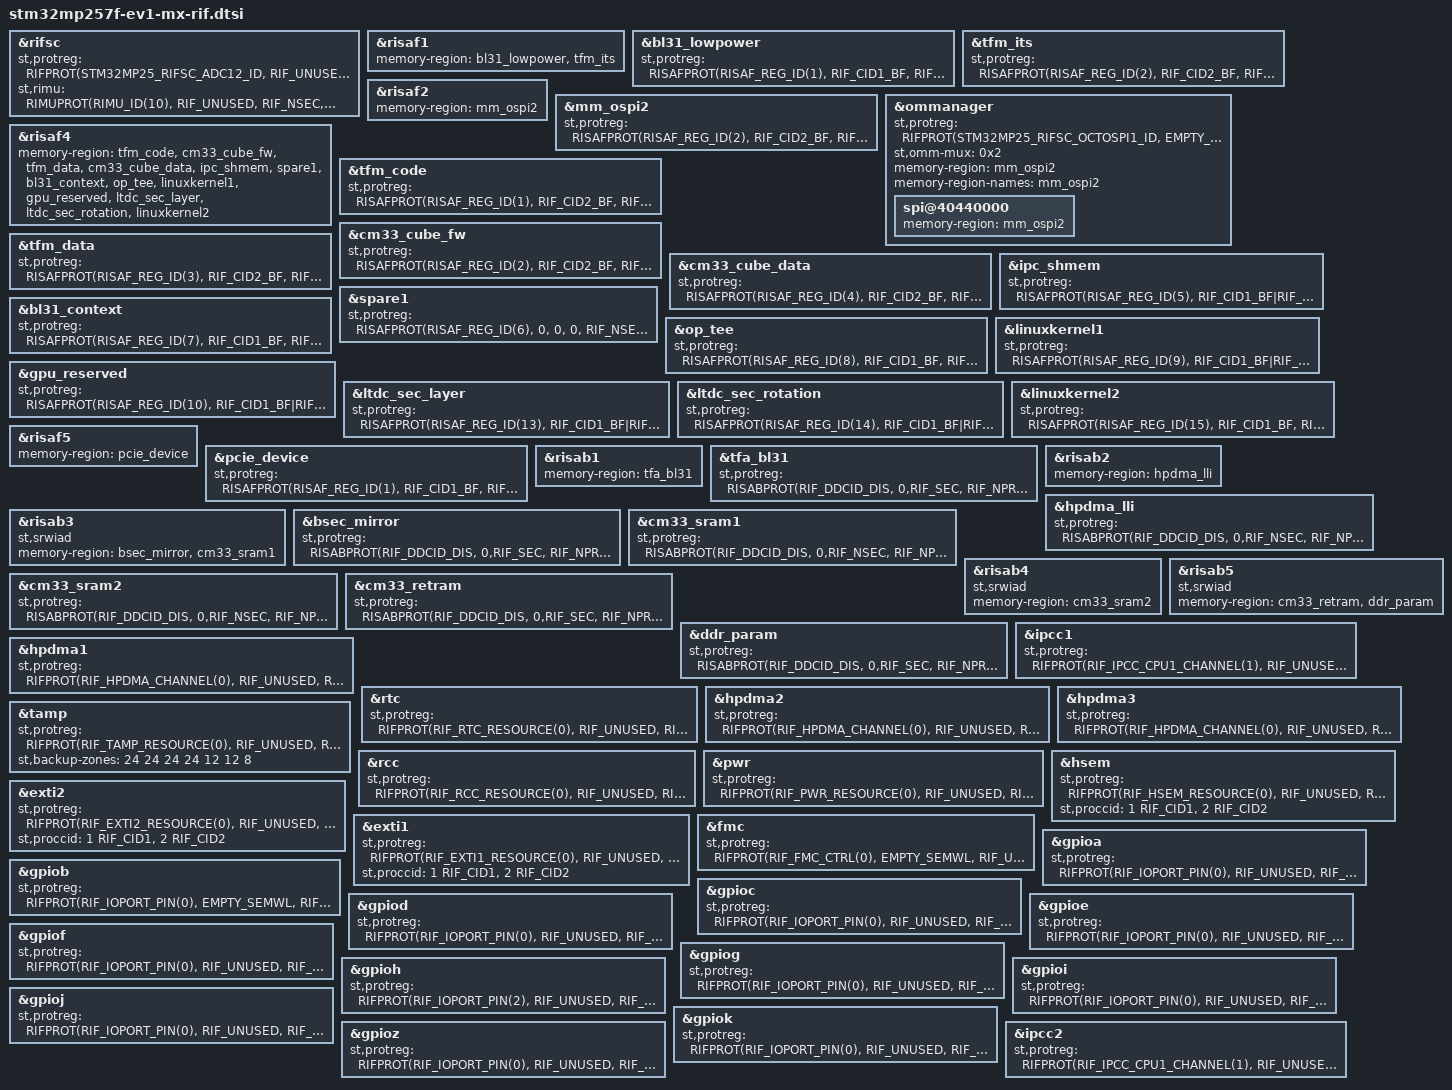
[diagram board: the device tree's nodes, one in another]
// SPDX-License-Identifier: (GPL-2.0-or-later OR BSD-3-Clause)
/*
 * Copyright (C) 2024, STMicroelectronics - All Rights Reserved
 * Author: STM32CubeMX code generation for STMicroelectronics.
 */

/* For more information on Device Tree configuration, please refer to
 * https://wiki.st.com/stm32mpu/wiki/Category:Device_tree_configuration
 */

&rifsc{
	status = "okay";
	st,protreg = <
		RIFPROT(STM32MP25_RIFSC_ADC12_ID, RIF_UNUSED, RIF_UNLOCK, RIF_NSEC, RIF_PRIV, RIF_CID1, RIF_SEM_DIS, RIF_CFEN)
		RIFPROT(STM32MP25_RIFSC_ADC3_ID, RIF_UNUSED, RIF_UNLOCK, RIF_NSEC, RIF_NPRIV, RIF_CID2, RIF_SEM_DIS, RIF_CFEN)
		RIFPROT(STM32MP25_RIFSC_ADF1_ID, EMPTY_SEMWL, RIF_UNLOCK, RIF_NSEC, RIF_NPRIV, RIF_UNUSED, RIF_SEM_EN, RIF_CFEN)
		RIFPROT(STM32MP25_RIFSC_COMBOPHY_ID, RIF_UNUSED, RIF_UNLOCK, RIF_NSEC, RIF_PRIV, RIF_CID1, RIF_SEM_DIS, RIF_CFEN)
		RIFPROT(STM32MP25_RIFSC_CRC_ID, RIF_UNUSED, RIF_UNLOCK, RIF_NSEC, RIF_NPRIV, RIF_CID2, RIF_SEM_DIS, RIF_CFEN)
		RIFPROT(STM32MP25_RIFSC_CRYP1_ID, RIF_UNUSED, RIF_UNLOCK, RIF_NSEC, RIF_PRIV, RIF_CID1, RIF_SEM_DIS, RIF_CFEN)
		RIFPROT(STM32MP25_RIFSC_CRYP2_ID, RIF_UNUSED, RIF_UNLOCK, RIF_SEC, RIF_PRIV, RIF_CID2, RIF_SEM_DIS, RIF_CFEN)
		RIFPROT(STM32MP25_RIFSC_CSI_ID, RIF_UNUSED, RIF_UNLOCK, RIF_NSEC, RIF_PRIV, RIF_CID1, RIF_SEM_DIS, RIF_CFEN)
		RIFPROT(STM32MP25_RIFSC_DCMIPP_ID, RIF_UNUSED, RIF_UNLOCK, RIF_NSEC, RIF_PRIV, RIF_CID1, RIF_SEM_DIS, RIF_CFEN)
		RIFPROT(STM32MP25_RIFSC_DCMI_PSSI_ID, EMPTY_SEMWL, RIF_UNLOCK, RIF_NSEC, RIF_NPRIV, RIF_UNUSED, RIF_SEM_EN, RIF_CFEN)
		RIFPROT(STM32MP25_RIFSC_DSI_RDFIFO_ID, RIF_UNUSED, RIF_UNLOCK, RIF_NSEC, RIF_PRIV, RIF_CID1, RIF_SEM_DIS, RIF_CFEN)
		RIFPROT(STM32MP25_RIFSC_DSI_TRIG_ID, RIF_UNUSED, RIF_UNLOCK, RIF_NSEC, RIF_PRIV, RIF_CID1, RIF_SEM_DIS, RIF_CFEN)
		RIFPROT(STM32MP25_RIFSC_DSI_CMN_ID, RIF_UNUSED, RIF_UNLOCK, RIF_NSEC, RIF_PRIV, RIF_CID1, RIF_SEM_DIS, RIF_CFEN)
		RIFPROT(STM32MP25_RIFSC_DTS_ID, RIF_UNUSED, RIF_UNLOCK, RIF_NSEC, RIF_PRIV, RIF_CID1, RIF_SEM_DIS, RIF_CFEN)
		RIFPROT(STM32MP25_RIFSC_ETH1_ID, RIF_UNUSED, RIF_UNLOCK, RIF_NSEC, RIF_PRIV, RIF_CID1, RIF_SEM_DIS, RIF_CFEN)
		RIFPROT(STM32MP25_RIFSC_ETH2_ID, RIF_UNUSED, RIF_UNLOCK, RIF_NSEC, RIF_PRIV, RIF_CID1, RIF_SEM_DIS, RIF_CFEN)
		RIFPROT(STM32MP25_RIFSC_ETHSW_ACM_CFG_ID, RIF_UNUSED, RIF_UNLOCK, RIF_NSEC, RIF_PRIV, RIF_CID1, RIF_SEM_DIS, RIF_CFEN)
		RIFPROT(STM32MP25_RIFSC_ETHSW_ACM_MSGBUF_ID, RIF_UNUSED, RIF_UNLOCK, RIF_NSEC, RIF_PRIV, RIF_CID1, RIF_SEM_DIS, RIF_CFEN)
		RIFPROT(STM32MP25_RIFSC_ETHSW_DEIP_ID, RIF_UNUSED, RIF_UNLOCK, RIF_NSEC, RIF_PRIV, RIF_CID1, RIF_SEM_DIS, RIF_CFEN)
		RIFPROT(STM32MP25_RIFSC_FDCAN_ID, EMPTY_SEMWL, RIF_UNLOCK, RIF_NSEC, RIF_PRIV, RIF_UNUSED, RIF_SEM_EN, RIF_CFEN)
		RIFPROT(STM32MP25_RIFSC_GICV2M_ID, RIF_UNUSED, RIF_UNLOCK, RIF_NSEC, RIF_PRIV, RIF_CID1, RIF_SEM_DIS, RIF_CFEN)
		RIFPROT(STM32MP25_RIFSC_GPU_ID, RIF_UNUSED, RIF_UNLOCK, RIF_NSEC, RIF_PRIV, RIF_CID1, RIF_SEM_DIS, RIF_CFEN)
		RIFPROT(STM32MP25_RIFSC_HASH_ID, RIF_UNUSED, RIF_LOCK, RIF_SEC, RIF_PRIV, RIF_CID1, RIF_SEM_DIS, RIF_CFEN)
		RIFPROT(STM32MP25_RIFSC_HDP_ID, EMPTY_SEMWL, RIF_UNLOCK, RIF_NSEC, RIF_NPRIV, RIF_UNUSED, RIF_SEM_EN, RIF_CFEN)
		RIFPROT(STM32MP25_RIFSC_I2C1_ID, RIF_UNUSED, RIF_UNLOCK, RIF_NSEC, RIF_NPRIV, RIF_CID2, RIF_SEM_DIS, RIF_CFEN)
		RIFPROT(STM32MP25_RIFSC_I2C2_ID, RIF_UNUSED, RIF_UNLOCK, RIF_NSEC, RIF_PRIV, RIF_CID1, RIF_SEM_DIS, RIF_CFEN)
		RIFPROT(STM32MP25_RIFSC_I2C3_ID, EMPTY_SEMWL, RIF_UNLOCK, RIF_NSEC, RIF_NPRIV, RIF_UNUSED, RIF_SEM_EN, RIF_CFEN)
		RIFPROT(STM32MP25_RIFSC_I2C4_ID, EMPTY_SEMWL, RIF_UNLOCK, RIF_NSEC, RIF_NPRIV, RIF_UNUSED, RIF_SEM_EN, RIF_CFEN)
		RIFPROT(STM32MP25_RIFSC_I2C5_ID, EMPTY_SEMWL, RIF_UNLOCK, RIF_NSEC, RIF_NPRIV, RIF_UNUSED, RIF_SEM_EN, RIF_CFEN)
		RIFPROT(STM32MP25_RIFSC_I2C6_ID, EMPTY_SEMWL, RIF_UNLOCK, RIF_NSEC, RIF_NPRIV, RIF_UNUSED, RIF_SEM_EN, RIF_CFEN)
		RIFPROT(STM32MP25_RIFSC_I2C7_ID, RIF_UNUSED, RIF_UNLOCK, RIF_SEC, RIF_PRIV, RIF_CID1, RIF_SEM_DIS, RIF_CFEN)
		RIFPROT(STM32MP25_RIFSC_I2C8_ID, EMPTY_SEMWL, RIF_UNLOCK, RIF_NSEC, RIF_PRIV, RIF_UNUSED, RIF_SEM_EN, RIF_CFEN)
		RIFPROT(STM32MP25_RIFSC_I3C1_ID, EMPTY_SEMWL, RIF_UNLOCK, RIF_NSEC, RIF_NPRIV, RIF_UNUSED, RIF_SEM_EN, RIF_CFEN)
		RIFPROT(STM32MP25_RIFSC_I3C2_ID, EMPTY_SEMWL, RIF_UNLOCK, RIF_NSEC, RIF_NPRIV, RIF_UNUSED, RIF_SEM_EN, RIF_CFEN)
		RIFPROT(STM32MP25_RIFSC_I3C3_ID, EMPTY_SEMWL, RIF_UNLOCK, RIF_NSEC, RIF_NPRIV, RIF_UNUSED, RIF_SEM_EN, RIF_CFEN)
		RIFPROT(STM32MP25_RIFSC_I3C4_ID, EMPTY_SEMWL, RIF_UNLOCK, RIF_NSEC, RIF_NPRIV, RIF_UNUSED, RIF_SEM_EN, RIF_CFEN)
		RIFPROT(STM32MP25_RIFSC_IAC_ID, RIF_UNUSED, RIF_UNLOCK, RIF_SEC, RIF_PRIV, RIF_CID1, RIF_SEM_DIS, RIF_CFEN)
		RIFPROT(STM32MP25_RIFSC_ICACHE_DCACHE_ID, RIF_UNUSED, RIF_UNLOCK, RIF_NSEC, RIF_NPRIV, RIF_CID2, RIF_SEM_DIS, RIF_CFEN)
		RIFPROT(STM32MP25_RIFSC_IWDG1_ID, RIF_UNUSED, RIF_LOCK, RIF_SEC, RIF_PRIV, RIF_CID1, RIF_SEM_DIS, RIF_CFEN)
		RIFPROT(STM32MP25_RIFSC_IWDG2_ID, RIF_UNUSED, RIF_UNLOCK, RIF_NSEC, RIF_PRIV, RIF_CID1, RIF_SEM_DIS, RIF_CFEN)
		RIFPROT(STM32MP25_RIFSC_IWDG3_ID, RIF_UNUSED, RIF_UNLOCK, RIF_SEC, RIF_PRIV, RIF_CID2, RIF_SEM_DIS, RIF_CFEN)
		RIFPROT(STM32MP25_RIFSC_IWDG4_ID, RIF_UNUSED, RIF_UNLOCK, RIF_NSEC, RIF_NPRIV, RIF_CID2, RIF_SEM_DIS, RIF_CFEN)
		RIFPROT(STM32MP25_RIFSC_IWDG5_ID, EMPTY_SEMWL, RIF_UNLOCK, RIF_NSEC, RIF_NPRIV, RIF_UNUSED, RIF_SEM_EN, RIF_CFEN)
		RIFPROT(STM32MP25_RIFSC_LPTIM1_ID, RIF_UNUSED, RIF_UNLOCK, RIF_SEC, RIF_PRIV, RIF_CID1, RIF_SEM_DIS, RIF_CFEN)
		RIFPROT(STM32MP25_RIFSC_LPTIM2_ID, RIF_UNUSED, RIF_UNLOCK, RIF_NSEC, RIF_PRIV, RIF_CID1, RIF_SEM_DIS, RIF_CFEN)
		RIFPROT(STM32MP25_RIFSC_LPTIM3_ID, RIF_UNUSED, RIF_UNLOCK, RIF_NSEC, RIF_PRIV, RIF_CID1, RIF_SEM_DIS, RIF_CFEN)
		RIFPROT(STM32MP25_RIFSC_LPTIM4_ID, RIF_UNUSED, RIF_UNLOCK, RIF_NSEC, RIF_PRIV, RIF_CID1, RIF_SEM_DIS, RIF_CFEN)
		RIFPROT(STM32MP25_RIFSC_LPTIM5_ID, RIF_UNUSED, RIF_UNLOCK, RIF_NSEC, RIF_PRIV, RIF_CID1, RIF_SEM_DIS, RIF_CFEN)
		RIFPROT(STM32MP25_RIFSC_LPUART1_ID, EMPTY_SEMWL, RIF_UNLOCK, RIF_NSEC, RIF_PRIV, RIF_UNUSED, RIF_SEM_EN, RIF_CFEN)
		RIFPROT(STM32MP25_RIFSC_LTDC_L2_ID, RIF_UNUSED, RIF_UNLOCK, RIF_NSEC, RIF_PRIV, RIF_CID1, RIF_SEM_DIS, RIF_CFEN)
		RIFPROT(STM32MP25_RIFSC_LTDC_L0L1_ID, RIF_UNUSED, RIF_UNLOCK, RIF_NSEC, RIF_PRIV, RIF_CID1, RIF_SEM_DIS, RIF_CFEN)
		RIFPROT(STM32MP25_RIFSC_LTDC_ROT_ID, RIF_UNUSED, RIF_UNLOCK, RIF_NSEC, RIF_PRIV, RIF_CID1, RIF_SEM_DIS, RIF_CFEN)
		RIFPROT(STM32MP25_RIFSC_LTDC_CMN_ID, RIF_UNUSED, RIF_UNLOCK, RIF_NSEC, RIF_PRIV, RIF_CID1, RIF_SEM_DIS, RIF_CFEN)
		RIFPROT(STM32MP25_RIFSC_LVDS_ID, RIF_UNUSED, RIF_UNLOCK, RIF_NSEC, RIF_PRIV, RIF_CID1, RIF_SEM_DIS, RIF_CFEN)
		RIFPROT(STM32MP25_RIFSC_MDF1_ID, EMPTY_SEMWL, RIF_UNLOCK, RIF_NSEC, RIF_PRIV, RIF_UNUSED, RIF_SEM_EN, RIF_CFEN)
		RIFPROT(STM32MP25_RIFSC_PCIE_ID, RIF_UNUSED, RIF_UNLOCK, RIF_NSEC, RIF_PRIV, RIF_CID1, RIF_SEM_DIS, RIF_CFEN)
		RIFPROT(STM32MP25_RIFSC_PKA_ID, RIF_UNUSED, RIF_LOCK, RIF_SEC, RIF_PRIV, RIF_CID1, RIF_SEM_DIS, RIF_CFEN)
		RIFPROT(STM32MP25_RIFSC_RAMCFG_ID, RIF_UNUSED, RIF_UNLOCK, RIF_SEC, RIF_PRIV, RIF_CID1, RIF_SEM_DIS, RIF_CFEN)
		RIFPROT(STM32MP25_RIFSC_RNG_ID, RIF_UNUSED, RIF_LOCK, RIF_SEC, RIF_PRIV, RIF_CID1, RIF_SEM_DIS, RIF_CFEN)
		RIFPROT(STM32MP25_RIFSC_SAES_ID, RIF_CID1_BF|RIF_CID2_BF, RIF_LOCK, RIF_SEC, RIF_PRIV, RIF_UNUSED, RIF_SEM_EN, RIF_CFEN)
		RIFPROT(STM32MP25_RIFSC_SAI1_ID, EMPTY_SEMWL, RIF_UNLOCK, RIF_NSEC, RIF_NPRIV, RIF_UNUSED, RIF_SEM_EN, RIF_CFEN)
		RIFPROT(STM32MP25_RIFSC_SAI2_ID, EMPTY_SEMWL, RIF_UNLOCK, RIF_NSEC, RIF_PRIV, RIF_UNUSED, RIF_SEM_EN, RIF_CFEN)
		RIFPROT(STM32MP25_RIFSC_SAI3_ID, EMPTY_SEMWL, RIF_UNLOCK, RIF_NSEC, RIF_NPRIV, RIF_UNUSED, RIF_SEM_EN, RIF_CFEN)
		RIFPROT(STM32MP25_RIFSC_SAI4_ID, EMPTY_SEMWL, RIF_UNLOCK, RIF_NSEC, RIF_NPRIV, RIF_UNUSED, RIF_SEM_EN, RIF_CFEN)
		RIFPROT(STM32MP25_RIFSC_SDMMC1_ID, RIF_UNUSED, RIF_UNLOCK, RIF_NSEC, RIF_PRIV, RIF_CID1, RIF_SEM_DIS, RIF_CFEN)
		RIFPROT(STM32MP25_RIFSC_SDMMC2_ID, EMPTY_SEMWL, RIF_UNLOCK, RIF_NSEC, RIF_PRIV, RIF_UNUSED, RIF_SEM_EN, RIF_CFEN)
		RIFPROT(STM32MP25_RIFSC_SDMMC3_ID, EMPTY_SEMWL, RIF_UNLOCK, RIF_NSEC, RIF_PRIV, RIF_UNUSED, RIF_SEM_EN, RIF_CFEN)
		RIFPROT(STM32MP25_RIFSC_SERC_ID, RIF_UNUSED, RIF_UNLOCK, RIF_SEC, RIF_PRIV, RIF_CID1, RIF_SEM_DIS, RIF_CFEN)
		RIFPROT(STM32MP25_RIFSC_SPDIFRX_ID, EMPTY_SEMWL, RIF_UNLOCK, RIF_NSEC, RIF_NPRIV, RIF_UNUSED, RIF_SEM_EN, RIF_CFEN)
		RIFPROT(STM32MP25_RIFSC_SPI1_ID, EMPTY_SEMWL, RIF_UNLOCK, RIF_NSEC, RIF_NPRIV, RIF_UNUSED, RIF_SEM_EN, RIF_CFEN)
		RIFPROT(STM32MP25_RIFSC_SPI2_ID, EMPTY_SEMWL, RIF_UNLOCK, RIF_NSEC, RIF_PRIV, RIF_UNUSED, RIF_SEM_EN, RIF_CFEN)
		RIFPROT(STM32MP25_RIFSC_SPI3_ID, EMPTY_SEMWL, RIF_UNLOCK, RIF_NSEC, RIF_PRIV, RIF_UNUSED, RIF_SEM_EN, RIF_CFEN)
		RIFPROT(STM32MP25_RIFSC_SPI4_ID, EMPTY_SEMWL, RIF_UNLOCK, RIF_NSEC, RIF_NPRIV, RIF_UNUSED, RIF_SEM_EN, RIF_CFEN)
		RIFPROT(STM32MP25_RIFSC_SPI5_ID, EMPTY_SEMWL, RIF_UNLOCK, RIF_NSEC, RIF_NPRIV, RIF_UNUSED, RIF_SEM_EN, RIF_CFEN)
		RIFPROT(STM32MP25_RIFSC_SPI6_ID, EMPTY_SEMWL, RIF_UNLOCK, RIF_NSEC, RIF_NPRIV, RIF_UNUSED, RIF_SEM_EN, RIF_CFEN)
		RIFPROT(STM32MP25_RIFSC_SPI7_ID, EMPTY_SEMWL, RIF_UNLOCK, RIF_NSEC, RIF_NPRIV, RIF_UNUSED, RIF_SEM_EN, RIF_CFEN)
		RIFPROT(STM32MP25_RIFSC_SPI8_ID, EMPTY_SEMWL, RIF_UNLOCK, RIF_NSEC, RIF_PRIV, RIF_UNUSED, RIF_SEM_EN, RIF_CFEN)
		RIFPROT(STM32MP25_RIFSC_STGEN_ID, RIF_UNUSED, RIF_LOCK, RIF_SEC, RIF_PRIV, RIF_CID1, RIF_SEM_DIS, RIF_CFEN)
		RIFPROT(STM32MP25_RIFSC_TIM1_ID, RIF_UNUSED, RIF_UNLOCK, RIF_NSEC, RIF_PRIV, RIF_CID1, RIF_SEM_DIS, RIF_CFEN)
		RIFPROT(STM32MP25_RIFSC_TIM2_ID, RIF_UNUSED, RIF_UNLOCK, RIF_NSEC, RIF_NPRIV, RIF_CID2, RIF_SEM_DIS, RIF_CFEN)
		RIFPROT(STM32MP25_RIFSC_TIM3_ID, RIF_UNUSED, RIF_UNLOCK, RIF_NSEC, RIF_PRIV, RIF_CID1, RIF_SEM_DIS, RIF_CFEN)
		RIFPROT(STM32MP25_RIFSC_TIM4_ID, RIF_UNUSED, RIF_UNLOCK, RIF_NSEC, RIF_PRIV, RIF_CID1, RIF_SEM_DIS, RIF_CFEN)
		RIFPROT(STM32MP25_RIFSC_TIM5_ID, RIF_UNUSED, RIF_UNLOCK, RIF_NSEC, RIF_PRIV, RIF_CID1, RIF_SEM_DIS, RIF_CFEN)
		RIFPROT(STM32MP25_RIFSC_TIM6_ID, RIF_UNUSED, RIF_UNLOCK, RIF_NSEC, RIF_PRIV, RIF_CID2, RIF_SEM_DIS, RIF_CFEN)
		RIFPROT(STM32MP25_RIFSC_TIM7_ID, RIF_UNUSED, RIF_UNLOCK, RIF_NSEC, RIF_PRIV, RIF_CID1, RIF_SEM_DIS, RIF_CFEN)
		RIFPROT(STM32MP25_RIFSC_TIM8_ID, RIF_UNUSED, RIF_UNLOCK, RIF_NSEC, RIF_PRIV, RIF_CID1, RIF_SEM_DIS, RIF_CFEN)
		RIFPROT(STM32MP25_RIFSC_TIM10_ID, RIF_UNUSED, RIF_UNLOCK, RIF_NSEC, RIF_PRIV, RIF_CID1, RIF_SEM_DIS, RIF_CFEN)
		RIFPROT(STM32MP25_RIFSC_TIM11_ID, RIF_UNUSED, RIF_UNLOCK, RIF_NSEC, RIF_PRIV, RIF_CID1, RIF_SEM_DIS, RIF_CFEN)
		RIFPROT(STM32MP25_RIFSC_TIM12_ID, RIF_UNUSED, RIF_UNLOCK, RIF_NSEC, RIF_PRIV, RIF_CID1, RIF_SEM_DIS, RIF_CFEN)
		RIFPROT(STM32MP25_RIFSC_TIM13_ID, RIF_UNUSED, RIF_UNLOCK, RIF_NSEC, RIF_PRIV, RIF_CID1, RIF_SEM_DIS, RIF_CFEN)
		RIFPROT(STM32MP25_RIFSC_TIM14_ID, RIF_UNUSED, RIF_UNLOCK, RIF_NSEC, RIF_PRIV, RIF_CID1, RIF_SEM_DIS, RIF_CFEN)
		RIFPROT(STM32MP25_RIFSC_TIM15_ID, RIF_UNUSED, RIF_UNLOCK, RIF_NSEC, RIF_PRIV, RIF_CID1, RIF_SEM_DIS, RIF_CFEN)
		RIFPROT(STM32MP25_RIFSC_TIM16_ID, RIF_UNUSED, RIF_UNLOCK, RIF_NSEC, RIF_PRIV, RIF_CID1, RIF_SEM_DIS, RIF_CFEN)
		RIFPROT(STM32MP25_RIFSC_TIM17_ID, RIF_UNUSED, RIF_UNLOCK, RIF_NSEC, RIF_PRIV, RIF_CID1, RIF_SEM_DIS, RIF_CFEN)
		RIFPROT(STM32MP25_RIFSC_TIM20_ID, RIF_UNUSED, RIF_UNLOCK, RIF_NSEC, RIF_PRIV, RIF_CID1, RIF_SEM_DIS, RIF_CFEN)
		RIFPROT(STM32MP25_RIFSC_UART4_ID, EMPTY_SEMWL, RIF_UNLOCK, RIF_NSEC, RIF_NPRIV, RIF_UNUSED, RIF_SEM_EN, RIF_CFEN)
		RIFPROT(STM32MP25_RIFSC_UART5_ID, RIF_UNUSED, RIF_UNLOCK, RIF_SEC, RIF_NPRIV, RIF_CID2, RIF_SEM_DIS, RIF_CFEN)
		RIFPROT(STM32MP25_RIFSC_USART6_ID, RIF_UNUSED, RIF_UNLOCK, RIF_SEC, RIF_NPRIV, RIF_CID2, RIF_SEM_DIS, RIF_CFEN)
		RIFPROT(STM32MP25_RIFSC_UART7_ID, EMPTY_SEMWL, RIF_UNLOCK, RIF_NSEC, RIF_NPRIV, RIF_UNUSED, RIF_SEM_EN, RIF_CFEN)
		RIFPROT(STM32MP25_RIFSC_UART8_ID, EMPTY_SEMWL, RIF_UNLOCK, RIF_NSEC, RIF_NPRIV, RIF_UNUSED, RIF_SEM_EN, RIF_CFEN)
		RIFPROT(STM32MP25_RIFSC_UART9_ID, EMPTY_SEMWL, RIF_UNLOCK, RIF_NSEC, RIF_NPRIV, RIF_UNUSED, RIF_SEM_EN, RIF_CFEN)
		RIFPROT(STM32MP25_RIFSC_UCPD1_ID, RIF_UNUSED, RIF_UNLOCK, RIF_NSEC, RIF_NPRIV, RIF_CID2, RIF_SEM_DIS, RIF_CFEN)
		RIFPROT(STM32MP25_RIFSC_USART1_ID, RIF_UNUSED, RIF_UNLOCK, RIF_NSEC, RIF_NPRIV, RIF_CID1, RIF_SEM_DIS, RIF_CFEN)
		RIFPROT(STM32MP25_RIFSC_USART2_ID, RIF_UNUSED, RIF_UNLOCK, RIF_NSEC, RIF_PRIV, RIF_CID1, RIF_SEM_DIS, RIF_CFEN)
		RIFPROT(STM32MP25_RIFSC_USART3_ID, EMPTY_SEMWL, RIF_UNLOCK, RIF_NSEC, RIF_NPRIV, RIF_UNUSED, RIF_SEM_EN, RIF_CFEN)
		RIFPROT(STM32MP25_RIFSC_USB3DR_ID, RIF_UNUSED, RIF_UNLOCK, RIF_NSEC, RIF_PRIV, RIF_CID1, RIF_SEM_DIS, RIF_CFEN)
		RIFPROT(STM32MP25_RIFSC_USBH_ID, RIF_UNUSED, RIF_UNLOCK, RIF_NSEC, RIF_PRIV, RIF_CID1, RIF_SEM_DIS, RIF_CFEN)
		RIFPROT(STM32MP25_RIFSC_VDEC_ID, RIF_UNUSED, RIF_UNLOCK, RIF_NSEC, RIF_PRIV, RIF_CID1, RIF_SEM_DIS, RIF_CFEN)
		RIFPROT(STM32MP25_RIFSC_VENC_ID, RIF_UNUSED, RIF_UNLOCK, RIF_NSEC, RIF_PRIV, RIF_CID1, RIF_SEM_DIS, RIF_CFEN)
		RIFPROT(STM32MP25_RIFSC_VREFBUF_ID, RIF_UNUSED, RIF_UNLOCK, RIF_SEC, RIF_PRIV, RIF_CID1, RIF_SEM_DIS, RIF_CFEN)
		RIFPROT(STM32MP25_RIFSC_WWDG1_ID, RIF_UNUSED, RIF_UNLOCK, RIF_NSEC, RIF_NPRIV, RIF_CID2, RIF_SEM_DIS, RIF_CFEN)
		RIFPROT(STM32MP25_RIFSC_WWDG2_ID, EMPTY_SEMWL, RIF_UNLOCK, RIF_NSEC, RIF_NPRIV, RIF_UNUSED, RIF_SEM_EN, RIF_CFEN)
	>;
	st,rimu = <
		RIMUPROT(RIMU_ID(10), RIF_UNUSED, RIF_NSEC, RIF_PRIV,RIF_CIDSEL_P) /* RIMU IP = DCMIPP */
		RIMUPROT(RIMU_ID(6), RIF_UNUSED, RIF_NSEC, RIF_PRIV,RIF_CIDSEL_P) /* RIMU IP = ETH1 */
		RIMUPROT(RIMU_ID(7), RIF_UNUSED, RIF_NSEC, RIF_PRIV,RIF_CIDSEL_P) /* RIMU IP = ETH2 */
		RIMUPROT(RIMU_ID(0), RIF_CID1, RIF_NSEC, RIF_NPRIV,RIF_CIDSEL_M) /* RIMU IP = ETR */
		RIMUPROT(RIMU_ID(9), RIF_UNUSED, RIF_NSEC, RIF_PRIV,RIF_CIDSEL_P) /* RIMU IP = GPU */
		RIMUPROT(RIMU_ID(11), RIF_CID4, RIF_NSEC, RIF_PRIV,RIF_CIDSEL_M) /* RIMU IP = LTDC_L1L2 */
		RIMUPROT(RIMU_ID(12), RIF_CID4, RIF_NSEC, RIF_PRIV,RIF_CIDSEL_M) /* RIMU IP = LTDC_L3 */
		RIMUPROT(RIMU_ID(13), RIF_CID4, RIF_NSEC, RIF_PRIV,RIF_CIDSEL_M) /* RIMU IP = LTDC_ROT */
		RIMUPROT(RIMU_ID(8), RIF_UNUSED, RIF_NSEC, RIF_PRIV,RIF_CIDSEL_P) /* RIMU IP = PCIE */
		RIMUPROT(RIMU_ID(1), RIF_UNUSED, RIF_NSEC, RIF_PRIV,RIF_CIDSEL_P) /* RIMU IP = SDMMC1 */
		RIMUPROT(RIMU_ID(2), RIF_UNUSED, RIF_NSEC, RIF_PRIV,RIF_CIDSEL_P) /* RIMU IP = SDMMC2 */
		RIMUPROT(RIMU_ID(3), RIF_UNUSED, RIF_NSEC, RIF_PRIV,RIF_CIDSEL_P) /* RIMU IP = SDMMC3 */
		RIMUPROT(RIMU_ID(4), RIF_UNUSED, RIF_NSEC, RIF_PRIV,RIF_CIDSEL_P) /* RIMU IP = USB3DR */
		RIMUPROT(RIMU_ID(5), RIF_UNUSED, RIF_NSEC, RIF_PRIV,RIF_CIDSEL_P) /* RIMU IP = USBH */
		RIMUPROT(RIMU_ID(14), RIF_UNUSED, RIF_NSEC, RIF_PRIV,RIF_CIDSEL_P) /* RIMU IP = VDEC */
		RIMUPROT(RIMU_ID(15), RIF_UNUSED, RIF_NSEC, RIF_PRIV,RIF_CIDSEL_P) /* RIMU IP = VENC */

	>;

	/* USER CODE BEGIN rifsc */
	/* USER CODE END rifsc */
};

&risaf1{

	memory-region = <&bl31_lowpower>, <&tfm_its>;
};

&bl31_lowpower{

	st,protreg = <RISAFPROT(RISAF_REG_ID(1), RIF_CID1_BF, RIF_CID1_BF, RIF_CID1_BF, RIF_SEC, RIF_ENC_DIS, RIF_BREN_EN)>;
};

&tfm_its{

	st,protreg = <RISAFPROT(RISAF_REG_ID(2), RIF_CID2_BF, RIF_CID2_BF, RIF_CID2_BF, RIF_SEC, RIF_ENC_DIS, RIF_BREN_EN)>;
};

&risaf2{

	memory-region = <&mm_ospi2>;
};

&mm_ospi2{

	st,protreg = <RISAFPROT(RISAF_REG_ID(2), RIF_CID2_BF, RIF_CID2_BF, RIF_CID1_BF, RIF_SEC, RIF_ENC_DIS, RIF_BREN_EN)>;
};

&ommanager{

	st,protreg = <
		RIFPROT(STM32MP25_RIFSC_OCTOSPI1_ID, EMPTY_SEMWL, RIF_UNLOCK, RIF_NSEC, RIF_NPRIV, RIF_UNUSED, RIF_SEM_EN, RIF_CFEN)
		RIFPROT(STM32MP25_RIFSC_OCTOSPI2_ID, RIF_UNUSED, RIF_UNLOCK, RIF_SEC, RIF_PRIV, RIF_CID1, RIF_SEM_DIS, RIF_CFEN)
		RIFPROT(STM32MP25_RIFSC_OCTOSPIM_ID, RIF_UNUSED, RIF_UNLOCK, RIF_SEC, RIF_PRIV, RIF_CID1, RIF_SEM_DIS, RIF_CFEN)
		RIFPROT(STM32MP25_RIFSC_OTFDEC1_ID, EMPTY_SEMWL, RIF_UNLOCK, RIF_NSEC, RIF_PRIV, RIF_UNUSED, RIF_SEM_EN, RIF_CFEN)
		RIFPROT(STM32MP25_RIFSC_OTFDEC2_ID, RIF_UNUSED, RIF_UNLOCK, RIF_SEC, RIF_PRIV, RIF_CID2, RIF_SEM_DIS, RIF_CFEN)
	>;

	/* USER CODE BEGIN ommanager */
	st,omm-mux = <0x2>;
	memory-region = <&mm_ospi2>;
	memory-region-names = "mm_ospi2";

	spi@40440000 {
		memory-region = <&mm_ospi2>;
		/* insert flash definition here */
	};
	/* USER CODE END ommanager */
};

&risaf4{

	memory-region = <&tfm_code>, <&cm33_cube_fw>, <&tfm_data>, <&cm33_cube_data>, <&ipc_shmem>, <&spare1>, <&bl31_context>, <&op_tee>, <&linuxkernel1>, <&gpu_reserved>, <&ltdc_sec_layer>, <&ltdc_sec_rotation>, <&linuxkernel2>;
};

&tfm_code{

	st,protreg = <RISAFPROT(RISAF_REG_ID(1), RIF_CID2_BF, RIF_CID2_BF, 0, RIF_SEC, RIF_ENC_EN, RIF_BREN_EN)>;
};

&cm33_cube_fw{

	st,protreg = <RISAFPROT(RISAF_REG_ID(2), RIF_CID2_BF, RIF_CID2_BF, 0, RIF_NSEC, RIF_ENC_DIS, RIF_BREN_EN)>;
};

&tfm_data{

	st,protreg = <RISAFPROT(RISAF_REG_ID(3), RIF_CID2_BF, RIF_CID2_BF, 0, RIF_SEC, RIF_ENC_EN, RIF_BREN_EN)>;
};

&cm33_cube_data{

	st,protreg = <RISAFPROT(RISAF_REG_ID(4), RIF_CID2_BF, RIF_CID2_BF, 0, RIF_NSEC, RIF_ENC_DIS, RIF_BREN_EN)>;
};

&ipc_shmem{

	st,protreg = <RISAFPROT(RISAF_REG_ID(5), RIF_CID1_BF|RIF_CID2_BF, RIF_CID1_BF|RIF_CID2_BF, 0, RIF_NSEC, RIF_ENC_DIS, RIF_BREN_EN)>;
};

&spare1{

	st,protreg = <RISAFPROT(RISAF_REG_ID(6), 0, 0, 0, RIF_NSEC, RIF_ENC_DIS, RIF_BREN_EN)>;
};

&bl31_context{

	st,protreg = <RISAFPROT(RISAF_REG_ID(7), RIF_CID1_BF, RIF_CID1_BF, RIF_CID1_BF, RIF_SEC, RIF_ENC_EN, RIF_BREN_EN)>;
};

&op_tee{

	st,protreg = <RISAFPROT(RISAF_REG_ID(8), RIF_CID1_BF, RIF_CID1_BF, 0, RIF_SEC, RIF_ENC_EN, RIF_BREN_EN)>;
};

&linuxkernel1{

	st,protreg = <RISAFPROT(RISAF_REG_ID(9), RIF_CID1_BF|RIF_CID4_BF, RIF_CID1_BF|RIF_CID4_BF, 0, RIF_NSEC, RIF_ENC_DIS, RIF_BREN_EN)>;
};

&gpu_reserved{

	st,protreg = <RISAFPROT(RISAF_REG_ID(10), RIF_CID1_BF|RIF_CID4_BF, RIF_CID1_BF|RIF_CID4_BF, 0, RIF_NSEC, RIF_ENC_DIS, RIF_BREN_EN)>;
};

&ltdc_sec_layer{

	st,protreg = <RISAFPROT(RISAF_REG_ID(13), RIF_CID1_BF|RIF_CID4_BF, RIF_CID1_BF|RIF_CID4_BF, 0, RIF_NSEC, RIF_ENC_DIS, RIF_BREN_EN)>;
};

&ltdc_sec_rotation{

	st,protreg = <RISAFPROT(RISAF_REG_ID(14), RIF_CID1_BF|RIF_CID4_BF, RIF_CID1_BF|RIF_CID4_BF, 0, RIF_NSEC, RIF_ENC_DIS, RIF_BREN_EN)>;
};

&linuxkernel2{

	st,protreg = <RISAFPROT(RISAF_REG_ID(15), RIF_CID1_BF, RIF_CID1_BF, 0, RIF_NSEC, RIF_ENC_DIS, RIF_BREN_EN)>;
};

&risaf5{

	memory-region = <&pcie_device>;
};

&pcie_device{

	st,protreg = <RISAFPROT(RISAF_REG_ID(1), RIF_CID1_BF, RIF_CID1_BF, 0, RIF_NSEC, RIF_ENC_DIS, RIF_BREN_EN)>;
};

&risab1{

	memory-region = <&tfa_bl31>;
};

&tfa_bl31{

	st,protreg = <RISABPROT(RIF_DDCID_DIS, 0,RIF_SEC, RIF_NPRIV, RIF_CFEN, RIF_CID1_BF, RIF_CID1_BF, RIF_CID1_BF)>;
};

&risab2{

	memory-region = <&hpdma_lli>;
};

&hpdma_lli{

	st,protreg = <RISABPROT(RIF_DDCID_DIS, 0,RIF_NSEC, RIF_NPRIV, RIF_CFEN, RIF_CID1_BF, RIF_CID1_BF, RIF_CID1_BF)>;
};

&risab3{

	st,srwiad;
	memory-region = <&bsec_mirror>, <&cm33_sram1>;
};

&bsec_mirror{

	st,protreg = <RISABPROT(RIF_DDCID_DIS, 0,RIF_SEC, RIF_NPRIV, RIF_CFEN, RIF_CID1_BF|RIF_CID2_BF, RIF_CID1_BF, RIF_CID1_BF|RIF_CID2_BF)>;
};

&cm33_sram1{

	st,protreg = <RISABPROT(RIF_DDCID_DIS, 0,RIF_NSEC, RIF_NPRIV, RIF_CFEN, RIF_CID2_BF, RIF_CID2_BF, 0)>;
};

&risab4{

	st,srwiad;
	memory-region = <&cm33_sram2>;
};

&cm33_sram2{

	st,protreg = <RISABPROT(RIF_DDCID_DIS, 0,RIF_NSEC, RIF_NPRIV, RIF_CFEN, RIF_CID2_BF, RIF_CID2_BF, 0)>;
};

&risab5{

	st,srwiad;
	memory-region = <&cm33_retram>, <&ddr_param>;
};

&cm33_retram{

	st,protreg = <RISABPROT(RIF_DDCID_DIS, 0,RIF_SEC, RIF_NPRIV, RIF_CFEN, RIF_CID2_BF, RIF_CID2_BF, 0)>;
};

&ddr_param{

	st,protreg = <RISABPROT(RIF_DDCID_DIS, 0,RIF_SEC, RIF_NPRIV, RIF_CFEN, RIF_CID1_BF, RIF_CID1_BF, RIF_CID1_BF)>;
};

&ipcc1{

	st,protreg = <
		RIFPROT(RIF_IPCC_CPU1_CHANNEL(1), RIF_UNUSED, RIF_UNLOCK, RIF_NSEC, RIF_NPRIV, RIF_CID1, RIF_SEM_DIS, RIF_CFEN) /* Feature = CPU1 channel 1 */
		RIFPROT(RIF_IPCC_CPU1_CHANNEL(2), RIF_UNUSED, RIF_UNLOCK, RIF_NSEC, RIF_NPRIV, RIF_CID1, RIF_SEM_DIS, RIF_CFEN) /* Feature = CPU1 channel 2 */
		RIFPROT(RIF_IPCC_CPU1_CHANNEL(3), RIF_UNUSED, RIF_UNLOCK, RIF_NSEC, RIF_NPRIV, RIF_CID1, RIF_SEM_DIS, RIF_CFEN) /* Feature = CPU1 channel 3 */
		RIFPROT(RIF_IPCC_CPU1_CHANNEL(4), RIF_UNUSED, RIF_UNLOCK, RIF_NSEC, RIF_NPRIV, RIF_CID1, RIF_SEM_DIS, RIF_CFEN) /* Feature = CPU1 channel 4 */
		RIFPROT(RIF_IPCC_CPU1_CHANNEL(5), RIF_UNUSED, RIF_UNLOCK, RIF_NSEC, RIF_NPRIV, RIF_CID1, RIF_SEM_DIS, RIF_CFEN) /* Feature = CPU1 channel 5 */
		RIFPROT(RIF_IPCC_CPU1_CHANNEL(6), RIF_UNUSED, RIF_UNLOCK, RIF_NSEC, RIF_NPRIV, RIF_CID1, RIF_SEM_DIS, RIF_CFEN) /* Feature = CPU1 channel 6 */
		RIFPROT(RIF_IPCC_CPU1_CHANNEL(7), RIF_UNUSED, RIF_UNLOCK, RIF_NSEC, RIF_NPRIV, RIF_CID1, RIF_SEM_DIS, RIF_CFEN) /* Feature = CPU1 channel 7 */
		RIFPROT(RIF_IPCC_CPU1_CHANNEL(8), RIF_UNUSED, RIF_UNLOCK, RIF_NSEC, RIF_NPRIV, RIF_CID1, RIF_SEM_DIS, RIF_CFEN) /* Feature = CPU1 channel 8 */
		RIFPROT(RIF_IPCC_CPU1_CHANNEL(9), RIF_UNUSED, RIF_UNLOCK, RIF_NSEC, RIF_NPRIV, RIF_CID1, RIF_SEM_DIS, RIF_CFEN) /* Feature = CPU1 channel 9 */
		RIFPROT(RIF_IPCC_CPU1_CHANNEL(10), RIF_UNUSED, RIF_UNLOCK, RIF_NSEC, RIF_NPRIV, RIF_CID1, RIF_SEM_DIS, RIF_CFEN) /* Feature = CPU1 channel 10 */
		RIFPROT(RIF_IPCC_CPU1_CHANNEL(11), RIF_UNUSED, RIF_UNLOCK, RIF_NSEC, RIF_NPRIV, RIF_CID1, RIF_SEM_DIS, RIF_CFEN) /* Feature = CPU1 channel 11 */
		RIFPROT(RIF_IPCC_CPU1_CHANNEL(12), RIF_UNUSED, RIF_UNLOCK, RIF_NSEC, RIF_NPRIV, RIF_CID1, RIF_SEM_DIS, RIF_CFEN) /* Feature = CPU1 channel 12 */
		RIFPROT(RIF_IPCC_CPU1_CHANNEL(13), RIF_UNUSED, RIF_UNLOCK, RIF_NSEC, RIF_NPRIV, RIF_CID1, RIF_SEM_DIS, RIF_CFEN) /* Feature = CPU1 channel 13 */
		RIFPROT(RIF_IPCC_CPU1_CHANNEL(14), RIF_UNUSED, RIF_UNLOCK, RIF_NSEC, RIF_NPRIV, RIF_CID1, RIF_SEM_DIS, RIF_CFEN) /* Feature = CPU1 channel 14 */
		RIFPROT(RIF_IPCC_CPU1_CHANNEL(15), RIF_UNUSED, RIF_UNLOCK, RIF_NSEC, RIF_NPRIV, RIF_CID1, RIF_SEM_DIS, RIF_CFEN) /* Feature = CPU1 channel 15 */
		RIFPROT(RIF_IPCC_CPU1_CHANNEL(16), RIF_UNUSED, RIF_UNLOCK, RIF_NSEC, RIF_NPRIV, RIF_CID1, RIF_SEM_DIS, RIF_CFEN) /* Feature = CPU1 channel 16 */
		RIFPROT(RIF_IPCC_CPU2_CHANNEL(1), RIF_UNUSED, RIF_UNLOCK, RIF_NSEC, RIF_NPRIV, RIF_CID2, RIF_SEM_DIS, RIF_CFEN) /* Feature = CPU2 channel 1 */
		RIFPROT(RIF_IPCC_CPU2_CHANNEL(2), RIF_UNUSED, RIF_UNLOCK, RIF_NSEC, RIF_NPRIV, RIF_CID2, RIF_SEM_DIS, RIF_CFEN) /* Feature = CPU2 channel 2 */
		RIFPROT(RIF_IPCC_CPU2_CHANNEL(3), RIF_UNUSED, RIF_UNLOCK, RIF_NSEC, RIF_NPRIV, RIF_CID2, RIF_SEM_DIS, RIF_CFEN) /* Feature = CPU2 channel 3 */
		RIFPROT(RIF_IPCC_CPU2_CHANNEL(4), RIF_UNUSED, RIF_UNLOCK, RIF_NSEC, RIF_NPRIV, RIF_CID2, RIF_SEM_DIS, RIF_CFEN) /* Feature = CPU2 channel 4 */
		RIFPROT(RIF_IPCC_CPU2_CHANNEL(5), RIF_UNUSED, RIF_UNLOCK, RIF_NSEC, RIF_NPRIV, RIF_CID2, RIF_SEM_DIS, RIF_CFEN) /* Feature = CPU2 channel 5 */
		RIFPROT(RIF_IPCC_CPU2_CHANNEL(6), RIF_UNUSED, RIF_UNLOCK, RIF_NSEC, RIF_NPRIV, RIF_CID2, RIF_SEM_DIS, RIF_CFEN) /* Feature = CPU2 channel 6 */
		RIFPROT(RIF_IPCC_CPU2_CHANNEL(7), RIF_UNUSED, RIF_UNLOCK, RIF_NSEC, RIF_NPRIV, RIF_CID2, RIF_SEM_DIS, RIF_CFEN) /* Feature = CPU2 channel 7 */
		RIFPROT(RIF_IPCC_CPU2_CHANNEL(8), RIF_UNUSED, RIF_UNLOCK, RIF_NSEC, RIF_NPRIV, RIF_CID2, RIF_SEM_DIS, RIF_CFEN) /* Feature = CPU2 channel 8 */
		RIFPROT(RIF_IPCC_CPU2_CHANNEL(9), RIF_UNUSED, RIF_UNLOCK, RIF_NSEC, RIF_NPRIV, RIF_CID2, RIF_SEM_DIS, RIF_CFEN) /* Feature = CPU2 channel 9 */
		RIFPROT(RIF_IPCC_CPU2_CHANNEL(10), RIF_UNUSED, RIF_UNLOCK, RIF_NSEC, RIF_NPRIV, RIF_CID2, RIF_SEM_DIS, RIF_CFEN) /* Feature = CPU2 channel 10 */
		RIFPROT(RIF_IPCC_CPU2_CHANNEL(11), RIF_UNUSED, RIF_UNLOCK, RIF_NSEC, RIF_NPRIV, RIF_CID2, RIF_SEM_DIS, RIF_CFEN) /* Feature = CPU2 channel 11 */
		RIFPROT(RIF_IPCC_CPU2_CHANNEL(12), RIF_UNUSED, RIF_UNLOCK, RIF_NSEC, RIF_NPRIV, RIF_CID2, RIF_SEM_DIS, RIF_CFEN) /* Feature = CPU2 channel 12 */
		RIFPROT(RIF_IPCC_CPU2_CHANNEL(13), RIF_UNUSED, RIF_UNLOCK, RIF_NSEC, RIF_NPRIV, RIF_CID2, RIF_SEM_DIS, RIF_CFEN) /* Feature = CPU2 channel 13 */
		RIFPROT(RIF_IPCC_CPU2_CHANNEL(14), RIF_UNUSED, RIF_UNLOCK, RIF_NSEC, RIF_NPRIV, RIF_CID2, RIF_SEM_DIS, RIF_CFEN) /* Feature = CPU2 channel 14 */
		RIFPROT(RIF_IPCC_CPU2_CHANNEL(15), RIF_UNUSED, RIF_UNLOCK, RIF_NSEC, RIF_NPRIV, RIF_CID2, RIF_SEM_DIS, RIF_CFEN) /* Feature = CPU2 channel 15 */
		RIFPROT(RIF_IPCC_CPU2_CHANNEL(16), RIF_UNUSED, RIF_UNLOCK, RIF_NSEC, RIF_NPRIV, RIF_CID2, RIF_SEM_DIS, RIF_CFEN) /* Feature = CPU2 channel 16 */
	>;
};

&hpdma1{

	st,protreg = <
		RIFPROT(RIF_HPDMA_CHANNEL(0), RIF_UNUSED, RIF_UNLOCK, RIF_NSEC, RIF_PRIV, RIF_CID1, RIF_SEM_DIS, RIF_CFEN) /* Feature = HPDMA1 channel 0 */
		RIFPROT(RIF_HPDMA_CHANNEL(1), RIF_UNUSED, RIF_UNLOCK, RIF_NSEC, RIF_PRIV, RIF_CID1, RIF_SEM_DIS, RIF_CFEN) /* Feature = HPDMA1 channel 1 */
		RIFPROT(RIF_HPDMA_CHANNEL(2), RIF_UNUSED, RIF_UNLOCK, RIF_NSEC, RIF_PRIV, RIF_CID1, RIF_SEM_DIS, RIF_CFEN) /* Feature = HPDMA1 channel 2 */
		RIFPROT(RIF_HPDMA_CHANNEL(3), RIF_UNUSED, RIF_UNLOCK, RIF_NSEC, RIF_PRIV, RIF_CID1, RIF_SEM_DIS, RIF_CFEN) /* Feature = HPDMA1 channel 3 */
		RIFPROT(RIF_HPDMA_CHANNEL(4), RIF_UNUSED, RIF_UNLOCK, RIF_NSEC, RIF_PRIV, RIF_CID1, RIF_SEM_DIS, RIF_CFEN) /* Feature = HPDMA1 channel 4 */
		RIFPROT(RIF_HPDMA_CHANNEL(5), RIF_UNUSED, RIF_UNLOCK, RIF_NSEC, RIF_PRIV, RIF_CID1, RIF_SEM_DIS, RIF_CFEN) /* Feature = HPDMA1 channel 5 */
		RIFPROT(RIF_HPDMA_CHANNEL(6), RIF_UNUSED, RIF_UNLOCK, RIF_NSEC, RIF_PRIV, RIF_CID1, RIF_SEM_DIS, RIF_CFEN) /* Feature = HPDMA1 channel 6 */
		RIFPROT(RIF_HPDMA_CHANNEL(7), RIF_UNUSED, RIF_UNLOCK, RIF_NSEC, RIF_PRIV, RIF_CID1, RIF_SEM_DIS, RIF_CFEN) /* Feature = HPDMA1 channel 7 */
		RIFPROT(RIF_HPDMA_CHANNEL(8), RIF_UNUSED, RIF_UNLOCK, RIF_NSEC, RIF_PRIV, RIF_CID1, RIF_SEM_DIS, RIF_CFEN) /* Feature = HPDMA1 channel 8 */
		RIFPROT(RIF_HPDMA_CHANNEL(9), RIF_UNUSED, RIF_UNLOCK, RIF_NSEC, RIF_PRIV, RIF_CID1, RIF_SEM_DIS, RIF_CFEN) /* Feature = HPDMA1 channel 9 */
		RIFPROT(RIF_HPDMA_CHANNEL(10), RIF_UNUSED, RIF_UNLOCK, RIF_NSEC, RIF_PRIV, RIF_CID1, RIF_SEM_DIS, RIF_CFEN) /* Feature = HPDMA1 channel 10 */
		RIFPROT(RIF_HPDMA_CHANNEL(11), RIF_UNUSED, RIF_UNLOCK, RIF_NSEC, RIF_PRIV, RIF_CID1, RIF_SEM_DIS, RIF_CFEN) /* Feature = HPDMA1 channel 11 */
		RIFPROT(RIF_HPDMA_CHANNEL(12), RIF_UNUSED, RIF_UNLOCK, RIF_NSEC, RIF_PRIV, RIF_CID1, RIF_SEM_DIS, RIF_CFEN) /* Feature = HPDMA1 channel 12 */
		RIFPROT(RIF_HPDMA_CHANNEL(13), RIF_UNUSED, RIF_UNLOCK, RIF_NSEC, RIF_PRIV, RIF_CID1, RIF_SEM_DIS, RIF_CFEN) /* Feature = HPDMA1 channel 13 */
		RIFPROT(RIF_HPDMA_CHANNEL(14), RIF_UNUSED, RIF_UNLOCK, RIF_NSEC, RIF_PRIV, RIF_CID1, RIF_SEM_DIS, RIF_CFEN) /* Feature = HPDMA1 channel 14 */
		RIFPROT(RIF_HPDMA_CHANNEL(15), RIF_UNUSED, RIF_UNLOCK, RIF_NSEC, RIF_PRIV, RIF_CID1, RIF_SEM_DIS, RIF_CFEN) /* Feature = HPDMA1 channel 15 */
	>;
};

&rtc{

	st,protreg = <
		RIFPROT(RIF_RTC_RESOURCE(0), RIF_UNUSED, RIF_UNLOCK, RIF_NSEC, RIF_PRIV, RIF_CID1, RIF_SEM_DIS, RIF_CFEN) /* Feature = Alarm A */
		RIFPROT(RIF_RTC_RESOURCE(1), RIF_UNUSED, RIF_UNLOCK, RIF_NSEC, RIF_NPRIV, RIF_CID2, RIF_SEM_DIS, RIF_CFEN) /* Feature = Alarm B */
		RIFPROT(RIF_RTC_RESOURCE(2), RIF_UNUSED, RIF_UNLOCK, RIF_NSEC, RIF_PRIV, RIF_CID1, RIF_SEM_DIS, RIF_CFEN) /* Feature = Wakeup timer */
		RIFPROT(RIF_RTC_RESOURCE(3), RIF_UNUSED, RIF_UNLOCK, RIF_NSEC, RIF_PRIV, RIF_CID1, RIF_SEM_DIS, RIF_CFEN) /* Feature = Timestamp */
		RIFPROT(RIF_RTC_RESOURCE(4), RIF_UNUSED, RIF_UNLOCK, RIF_NSEC, RIF_PRIV, RIF_CID1, RIF_SEM_DIS, RIF_CFEN) /* Feature = Calibration */
		RIFPROT(RIF_RTC_RESOURCE(5), RIF_UNUSED, RIF_UNLOCK, RIF_NSEC, RIF_PRIV, RIF_CID1, RIF_SEM_DIS, RIF_CFEN) /* Feature = Initialization */
	>;
};

&hpdma2{

	st,protreg = <
		RIFPROT(RIF_HPDMA_CHANNEL(0), RIF_UNUSED, RIF_UNLOCK, RIF_NSEC, RIF_PRIV, RIF_CID1, RIF_SEM_DIS, RIF_CFEN) /* Feature = HPDMA2 channel 0 */
		RIFPROT(RIF_HPDMA_CHANNEL(1), RIF_UNUSED, RIF_UNLOCK, RIF_NSEC, RIF_PRIV, RIF_CID1, RIF_SEM_DIS, RIF_CFEN) /* Feature = HPDMA2 channel 1 */
		RIFPROT(RIF_HPDMA_CHANNEL(2), RIF_UNUSED, RIF_UNLOCK, RIF_NSEC, RIF_PRIV, RIF_CID1, RIF_SEM_DIS, RIF_CFEN) /* Feature = HPDMA2 channel 2 */
		RIFPROT(RIF_HPDMA_CHANNEL(3), RIF_UNUSED, RIF_UNLOCK, RIF_NSEC, RIF_PRIV, RIF_CID1, RIF_SEM_DIS, RIF_CFEN) /* Feature = HPDMA2 channel 3 */
		RIFPROT(RIF_HPDMA_CHANNEL(4), RIF_UNUSED, RIF_UNLOCK, RIF_NSEC, RIF_PRIV, RIF_CID1, RIF_SEM_DIS, RIF_CFEN) /* Feature = HPDMA2 channel 4 */
		RIFPROT(RIF_HPDMA_CHANNEL(5), RIF_UNUSED, RIF_UNLOCK, RIF_NSEC, RIF_PRIV, RIF_CID1, RIF_SEM_DIS, RIF_CFEN) /* Feature = HPDMA2 channel 5 */
		RIFPROT(RIF_HPDMA_CHANNEL(6), RIF_UNUSED, RIF_UNLOCK, RIF_NSEC, RIF_NPRIV, RIF_CID1, RIF_SEM_DIS, RIF_CFEN) /* Feature = HPDMA2 channel 6 */
		RIFPROT(RIF_HPDMA_CHANNEL(7), RIF_UNUSED, RIF_UNLOCK, RIF_NSEC, RIF_PRIV, RIF_CID1, RIF_SEM_DIS, RIF_CFEN) /* Feature = HPDMA2 channel 7 */
		RIFPROT(RIF_HPDMA_CHANNEL(8), RIF_UNUSED, RIF_UNLOCK, RIF_NSEC, RIF_PRIV, RIF_CID1, RIF_SEM_DIS, RIF_CFEN) /* Feature = HPDMA2 channel 8 */
		RIFPROT(RIF_HPDMA_CHANNEL(9), RIF_UNUSED, RIF_UNLOCK, RIF_NSEC, RIF_PRIV, RIF_CID1, RIF_SEM_DIS, RIF_CFEN) /* Feature = HPDMA2 channel 9 */
		RIFPROT(RIF_HPDMA_CHANNEL(10), RIF_UNUSED, RIF_UNLOCK, RIF_NSEC, RIF_PRIV, RIF_CID1, RIF_SEM_DIS, RIF_CFEN) /* Feature = HPDMA2 channel 10 */
		RIFPROT(RIF_HPDMA_CHANNEL(11), RIF_UNUSED, RIF_UNLOCK, RIF_NSEC, RIF_PRIV, RIF_CID1, RIF_SEM_DIS, RIF_CFEN) /* Feature = HPDMA2 channel 11 */
		RIFPROT(RIF_HPDMA_CHANNEL(12), RIF_UNUSED, RIF_UNLOCK, RIF_NSEC, RIF_PRIV, RIF_CID1, RIF_SEM_DIS, RIF_CFEN) /* Feature = HPDMA2 channel 12 */
		RIFPROT(RIF_HPDMA_CHANNEL(13), RIF_UNUSED, RIF_UNLOCK, RIF_NSEC, RIF_PRIV, RIF_CID1, RIF_SEM_DIS, RIF_CFEN) /* Feature = HPDMA2 channel 13 */
		RIFPROT(RIF_HPDMA_CHANNEL(14), RIF_UNUSED, RIF_UNLOCK, RIF_NSEC, RIF_PRIV, RIF_CID1, RIF_SEM_DIS, RIF_CFEN) /* Feature = HPDMA2 channel 14 */
		RIFPROT(RIF_HPDMA_CHANNEL(15), RIF_UNUSED, RIF_UNLOCK, RIF_NSEC, RIF_PRIV, RIF_CID1, RIF_SEM_DIS, RIF_CFEN) /* Feature = HPDMA2 channel 15 */
	>;
};

&hpdma3{

	st,protreg = <
		RIFPROT(RIF_HPDMA_CHANNEL(0), RIF_UNUSED, RIF_UNLOCK, RIF_NSEC, RIF_PRIV, RIF_CID2, RIF_SEM_DIS, RIF_CFEN) /* Feature = HPDMA3 channel 0 */
		RIFPROT(RIF_HPDMA_CHANNEL(1), RIF_UNUSED, RIF_UNLOCK, RIF_NSEC, RIF_PRIV, RIF_CID2, RIF_SEM_DIS, RIF_CFEN) /* Feature = HPDMA3 channel 1 */
		RIFPROT(RIF_HPDMA_CHANNEL(2), RIF_UNUSED, RIF_UNLOCK, RIF_NSEC, RIF_PRIV, RIF_CID2, RIF_SEM_DIS, RIF_CFEN) /* Feature = HPDMA3 channel 2 */
		RIFPROT(RIF_HPDMA_CHANNEL(3), RIF_UNUSED, RIF_UNLOCK, RIF_NSEC, RIF_PRIV, RIF_CID2, RIF_SEM_DIS, RIF_CFEN) /* Feature = HPDMA3 channel 3 */
		RIFPROT(RIF_HPDMA_CHANNEL(4), RIF_UNUSED, RIF_UNLOCK, RIF_NSEC, RIF_PRIV, RIF_CID2, RIF_SEM_DIS, RIF_CFEN) /* Feature = HPDMA3 channel 4 */
		RIFPROT(RIF_HPDMA_CHANNEL(5), RIF_UNUSED, RIF_UNLOCK, RIF_NSEC, RIF_PRIV, RIF_CID2, RIF_SEM_DIS, RIF_CFEN) /* Feature = HPDMA3 channel 5 */
		RIFPROT(RIF_HPDMA_CHANNEL(6), RIF_UNUSED, RIF_UNLOCK, RIF_NSEC, RIF_PRIV, RIF_CID2, RIF_SEM_DIS, RIF_CFEN) /* Feature = HPDMA3 channel 6 */
		RIFPROT(RIF_HPDMA_CHANNEL(7), RIF_UNUSED, RIF_UNLOCK, RIF_NSEC, RIF_PRIV, RIF_CID2, RIF_SEM_DIS, RIF_CFEN) /* Feature = HPDMA3 channel 7 */
		RIFPROT(RIF_HPDMA_CHANNEL(8), RIF_UNUSED, RIF_UNLOCK, RIF_NSEC, RIF_PRIV, RIF_CID2, RIF_SEM_DIS, RIF_CFEN) /* Feature = HPDMA3 channel 8 */
		RIFPROT(RIF_HPDMA_CHANNEL(9), RIF_UNUSED, RIF_UNLOCK, RIF_NSEC, RIF_PRIV, RIF_CID2, RIF_SEM_DIS, RIF_CFEN) /* Feature = HPDMA3 channel 9 */
		RIFPROT(RIF_HPDMA_CHANNEL(10), RIF_UNUSED, RIF_UNLOCK, RIF_NSEC, RIF_PRIV, RIF_CID2, RIF_SEM_DIS, RIF_CFEN) /* Feature = HPDMA3 channel 10 */
		RIFPROT(RIF_HPDMA_CHANNEL(11), RIF_UNUSED, RIF_UNLOCK, RIF_NSEC, RIF_PRIV, RIF_CID2, RIF_SEM_DIS, RIF_CFEN) /* Feature = HPDMA3 channel 11 */
		RIFPROT(RIF_HPDMA_CHANNEL(12), RIF_UNUSED, RIF_UNLOCK, RIF_NSEC, RIF_PRIV, RIF_CID2, RIF_SEM_DIS, RIF_CFEN) /* Feature = HPDMA3 channel 12 */
		RIFPROT(RIF_HPDMA_CHANNEL(13), RIF_UNUSED, RIF_UNLOCK, RIF_NSEC, RIF_PRIV, RIF_CID2, RIF_SEM_DIS, RIF_CFEN) /* Feature = HPDMA3 channel 13 */
		RIFPROT(RIF_HPDMA_CHANNEL(14), RIF_UNUSED, RIF_UNLOCK, RIF_NSEC, RIF_PRIV, RIF_CID2, RIF_SEM_DIS, RIF_CFEN) /* Feature = HPDMA3 channel 14 */
		RIFPROT(RIF_HPDMA_CHANNEL(15), RIF_UNUSED, RIF_UNLOCK, RIF_NSEC, RIF_PRIV, RIF_CID2, RIF_SEM_DIS, RIF_CFEN) /* Feature = HPDMA3 channel 15 */
	>;
};

&tamp{

	st,protreg = <
		RIFPROT(RIF_TAMP_RESOURCE(0), RIF_UNUSED, RIF_UNLOCK, RIF_SEC, RIF_PRIV, RIF_CID1, RIF_SEM_DIS, RIF_CFEN) /* Feature = Resource 0 */
		RIFPROT(RIF_TAMP_RESOURCE(1), RIF_UNUSED, RIF_UNLOCK, RIF_SEC, RIF_PRIV, RIF_CID1, RIF_SEM_DIS, RIF_CFEN) /* Feature = Resource 1 */
		RIFPROT(RIF_TAMP_RESOURCE(2), RIF_UNUSED, RIF_UNLOCK, RIF_SEC, RIF_PRIV, RIF_CID2, RIF_SEM_DIS, RIF_CFEN) /* Feature = Resource 2 */
	>;
	st,backup-zones = <24 24 24 24 12 12 8>;
};

&rcc{

	st,protreg = <
		RIFPROT(RIF_RCC_RESOURCE(0), RIF_UNUSED, RIF_UNLOCK, RIF_SEC, RIF_PRIV, RIF_CID1, RIF_SEM_DIS, RIF_CFEN) /* Feature = CK_ICN_HS_MCU\nCK_ICN_LS_MCU */
		RIFPROT(RIF_RCC_RESOURCE(1), RIF_UNUSED, RIF_UNLOCK, RIF_SEC, RIF_PRIV, RIF_CID1, RIF_SEM_DIS, RIF_CFEN) /* Feature = CK_ICN_SDMMC */
		RIFPROT(RIF_RCC_RESOURCE(2), RIF_UNUSED, RIF_UNLOCK, RIF_SEC, RIF_NPRIV, RIF_CID1, RIF_SEM_DIS, RIF_CFEN) /* Feature = CK_ICN_DDR */
		RIFPROT(RIF_RCC_RESOURCE(3), RIF_UNUSED, RIF_UNLOCK, RIF_SEC, RIF_PRIV, RIF_CID1, RIF_SEM_DIS, RIF_CFEN) /* Feature = CK_ICN_DISPLAY */
		RIFPROT(RIF_RCC_RESOURCE(4), RIF_UNUSED, RIF_UNLOCK, RIF_SEC, RIF_PRIV, RIF_CID1, RIF_SEM_DIS, RIF_CFEN) /* Feature = CK_ICN_HSL */
		RIFPROT(RIF_RCC_RESOURCE(5), RIF_UNUSED, RIF_UNLOCK, RIF_SEC, RIF_NPRIV, RIF_CID1, RIF_SEM_DIS, RIF_CFEN) /* Feature = CK_ICN_NIC */
		RIFPROT(RIF_RCC_RESOURCE(6), RIF_UNUSED, RIF_UNLOCK, RIF_SEC, RIF_PRIV, RIF_CID1, RIF_SEM_DIS, RIF_CFEN) /* Feature = CK_ICN_VID */
		RIFPROT(RIF_RCC_RESOURCE(7), RIF_UNUSED, RIF_UNLOCK, RIF_SEC, RIF_PRIV, RIF_CID1, RIF_SEM_DIS, RIF_CFEN) /* Feature = CK_KER_LPTIM1,2 */
		RIFPROT(RIF_RCC_RESOURCE(8), RIF_UNUSED, RIF_UNLOCK, RIF_SEC, RIF_PRIV, RIF_CID1, RIF_SEM_DIS, RIF_CFEN) /* Feature = CK_KER_USART2,4 */
		RIFPROT(RIF_RCC_RESOURCE(9), RIF_UNUSED, RIF_UNLOCK, RIF_SEC, RIF_PRIV, RIF_CID1, RIF_SEM_DIS, RIF_CFEN) /* Feature = CK_KER_USART3,5 */
		RIFPROT(RIF_RCC_RESOURCE(10), EMPTY_SEMWL, RIF_UNLOCK, RIF_NSEC, RIF_PRIV, RIF_UNUSED, RIF_SEM_EN, RIF_CFEN) /* Feature = CK_KER_SPI2,3 */
		RIFPROT(RIF_RCC_RESOURCE(11), EMPTY_SEMWL, RIF_UNLOCK, RIF_NSEC, RIF_PRIV, RIF_UNUSED, RIF_SEM_EN, RIF_CFEN) /* Feature = CK_KER_SPDIFRX */
		RIFPROT(RIF_RCC_RESOURCE(12), RIF_UNUSED, RIF_UNLOCK, RIF_SEC, RIF_PRIV, RIF_CID1, RIF_SEM_DIS, RIF_CFEN) /* Feature = CK_KER_I2C1,2\nCK_KER_I3C1,2 */
		RIFPROT(RIF_RCC_RESOURCE(13), EMPTY_SEMWL, RIF_UNLOCK, RIF_NSEC, RIF_PRIV, RIF_UNUSED, RIF_SEM_EN, RIF_CFEN) /* Feature = CK_KER_I2C3,5\nCK_KER_I3C3 */
		RIFPROT(RIF_RCC_RESOURCE(14), EMPTY_SEMWL, RIF_UNLOCK, RIF_NSEC, RIF_PRIV, RIF_UNUSED, RIF_SEM_EN, RIF_CFEN) /* Feature = CK_KER_I2C4,6 */
		RIFPROT(RIF_RCC_RESOURCE(15), RIF_UNUSED, RIF_UNLOCK, RIF_SEC, RIF_PRIV, RIF_CID1, RIF_SEM_DIS, RIF_CFEN) /* Feature = CK_KER_I2C7 */
		RIFPROT(RIF_RCC_RESOURCE(16), EMPTY_SEMWL, RIF_UNLOCK, RIF_NSEC, RIF_PRIV, RIF_UNUSED, RIF_SEM_EN, RIF_CFEN) /* Feature = CK_KER_SPI1 */
		RIFPROT(RIF_RCC_RESOURCE(17), EMPTY_SEMWL, RIF_UNLOCK, RIF_NSEC, RIF_PRIV, RIF_UNUSED, RIF_SEM_EN, RIF_CFEN) /* Feature = CK_KER_SPI4,5 */
		RIFPROT(RIF_RCC_RESOURCE(18), EMPTY_SEMWL, RIF_UNLOCK, RIF_NSEC, RIF_PRIV, RIF_UNUSED, RIF_SEM_EN, RIF_CFEN) /* Feature = CK_KER_SPI6,7 */
		RIFPROT(RIF_RCC_RESOURCE(19), EMPTY_SEMWL, RIF_UNLOCK, RIF_NSEC, RIF_PRIV, RIF_UNUSED, RIF_SEM_EN, RIF_CFEN) /* Feature = CK_KER_USART1 */
		RIFPROT(RIF_RCC_RESOURCE(20), RIF_UNUSED, RIF_UNLOCK, RIF_SEC, RIF_PRIV, RIF_CID1, RIF_SEM_DIS, RIF_CFEN) /* Feature = CK_KER_USART6 */
		RIFPROT(RIF_RCC_RESOURCE(21), EMPTY_SEMWL, RIF_UNLOCK, RIF_NSEC, RIF_PRIV, RIF_UNUSED, RIF_SEM_EN, RIF_CFEN) /* Feature = CK_KER_UART7,8 */
		RIFPROT(RIF_RCC_RESOURCE(22), EMPTY_SEMWL, RIF_UNLOCK, RIF_NSEC, RIF_PRIV, RIF_UNUSED, RIF_SEM_EN, RIF_CFEN) /* Feature = CK_KER_UART9 */
		RIFPROT(RIF_RCC_RESOURCE(23), EMPTY_SEMWL, RIF_UNLOCK, RIF_NSEC, RIF_PRIV, RIF_UNUSED, RIF_SEM_EN, RIF_CFEN) /* Feature = CK_KER_SAI1\nCK_KER_MDF1 */
		RIFPROT(RIF_RCC_RESOURCE(24), EMPTY_SEMWL, RIF_UNLOCK, RIF_NSEC, RIF_PRIV, RIF_UNUSED, RIF_SEM_EN, RIF_CFEN) /* Feature = CK_KER_SAI2 */
		RIFPROT(RIF_RCC_RESOURCE(25), EMPTY_SEMWL, RIF_UNLOCK, RIF_NSEC, RIF_PRIV, RIF_UNUSED, RIF_SEM_EN, RIF_CFEN) /* Feature = CK_KER_SAI3,4 */
		RIFPROT(RIF_RCC_RESOURCE(26), EMPTY_SEMWL, RIF_UNLOCK, RIF_NSEC, RIF_PRIV, RIF_UNUSED, RIF_SEM_EN, RIF_CFEN) /* Feature = CK_KER_FDCAN */
		RIFPROT(RIF_RCC_RESOURCE(27), RIF_UNUSED, RIF_UNLOCK, RIF_SEC, RIF_PRIV, RIF_CID1, RIF_SEM_DIS, RIF_CFEN) /* Feature = CK_KER_LTDC */
		RIFPROT(RIF_RCC_RESOURCE(28), EMPTY_SEMWL, RIF_UNLOCK, RIF_NSEC, RIF_PRIV, RIF_UNUSED, RIF_SEM_EN, RIF_CFEN) /* Feature = CK_KER_DSIPHY */
		RIFPROT(RIF_RCC_RESOURCE(29), RIF_UNUSED, RIF_UNLOCK, RIF_SEC, RIF_PRIV, RIF_CID1, RIF_SEM_DIS, RIF_CFEN) /* Feature = CK_KER_DCMIPP */
		RIFPROT(RIF_RCC_RESOURCE(30), RIF_UNUSED, RIF_UNLOCK, RIF_SEC, RIF_PRIV, RIF_CID1, RIF_SEM_DIS, RIF_CFEN) /* Feature = CK_KER_CSITXESC */
		RIFPROT(RIF_RCC_RESOURCE(31), RIF_UNUSED, RIF_UNLOCK, RIF_SEC, RIF_PRIV, RIF_CID1, RIF_SEM_DIS, RIF_CFEN) /* Feature = CK_KER_CSIPHY */
		RIFPROT(RIF_RCC_RESOURCE(32), EMPTY_SEMWL, RIF_UNLOCK, RIF_NSEC, RIF_PRIV, RIF_UNUSED, RIF_SEM_EN, RIF_CFEN) /* Feature = CK_KER_LVDSPHY */
		RIFPROT(RIF_RCC_RESOURCE(33), RIF_UNUSED, RIF_UNLOCK, RIF_SEC, RIF_PRIV, RIF_CID1, RIF_SEM_DIS, RIF_CFEN) /* Feature = CK_KER_STGEN */
		RIFPROT(RIF_RCC_RESOURCE(34), RIF_UNUSED, RIF_UNLOCK, RIF_SEC, RIF_PRIV, RIF_CID1, RIF_SEM_DIS, RIF_CFEN) /* Feature = CK_KER_USB3PCIEPHY */
		RIFPROT(RIF_RCC_RESOURCE(35), RIF_UNUSED, RIF_UNLOCK, RIF_SEC, RIF_PRIV, RIF_CID1, RIF_SEM_DIS, RIF_CFEN) /* Feature = CK_KER_USBTC */
		RIFPROT(RIF_RCC_RESOURCE(36), EMPTY_SEMWL, RIF_UNLOCK, RIF_NSEC, RIF_PRIV, RIF_UNUSED, RIF_SEM_EN, RIF_CFEN) /* Feature = CK_KER_I3C4 */
		RIFPROT(RIF_RCC_RESOURCE(37), EMPTY_SEMWL, RIF_UNLOCK, RIF_NSEC, RIF_PRIV, RIF_UNUSED, RIF_SEM_EN, RIF_CFEN) /* Feature = CK_KER_SPI8 */
		RIFPROT(RIF_RCC_RESOURCE(38), EMPTY_SEMWL, RIF_UNLOCK, RIF_NSEC, RIF_PRIV, RIF_UNUSED, RIF_SEM_EN, RIF_CFEN) /* Feature = CK_KER_I2C8 */
		RIFPROT(RIF_RCC_RESOURCE(39), EMPTY_SEMWL, RIF_UNLOCK, RIF_NSEC, RIF_PRIV, RIF_UNUSED, RIF_SEM_EN, RIF_CFEN) /* Feature = CK_KER_LPUART1 */
		RIFPROT(RIF_RCC_RESOURCE(40), EMPTY_SEMWL, RIF_UNLOCK, RIF_NSEC, RIF_PRIV, RIF_UNUSED, RIF_SEM_EN, RIF_CFEN) /* Feature = CK_KER_LPTIM3 */
		RIFPROT(RIF_RCC_RESOURCE(41), EMPTY_SEMWL, RIF_UNLOCK, RIF_NSEC, RIF_PRIV, RIF_UNUSED, RIF_SEM_EN, RIF_CFEN) /* Feature = CK_KER_LPTIM4,5 */
		RIFPROT(RIF_RCC_RESOURCE(42), EMPTY_SEMWL, RIF_UNLOCK, RIF_NSEC, RIF_PRIV, RIF_UNUSED, RIF_SEM_EN, RIF_CFEN) /* Feature = CK_KER_ADF1 */
		RIFPROT(RIF_RCC_RESOURCE(43), RIF_UNUSED, RIF_UNLOCK, RIF_SEC, RIF_PRIV, RIF_CID1, RIF_SEM_DIS, RIF_CFEN) /* Feature = CK_KER_TSDBG */
		RIFPROT(RIF_RCC_RESOURCE(44), RIF_UNUSED, RIF_UNLOCK, RIF_SEC, RIF_PRIV, RIF_CID1, RIF_SEM_DIS, RIF_CFEN) /* Feature = CK_KER_TPIU */
		RIFPROT(RIF_RCC_RESOURCE(45), RIF_UNUSED, RIF_UNLOCK, RIF_SEC, RIF_PRIV, RIF_CID1, RIF_SEM_DIS, RIF_CFEN) /* Feature = CK_SYS_ATB\nCK_ICN_M_ETR */
		RIFPROT(RIF_RCC_RESOURCE(46), EMPTY_SEMWL, RIF_UNLOCK, RIF_NSEC, RIF_PRIV, RIF_UNUSED, RIF_SEM_EN, RIF_CFEN) /* Feature = CK_KER_ADC12 */
		RIFPROT(RIF_RCC_RESOURCE(47), RIF_UNUSED, RIF_UNLOCK, RIF_SEC, RIF_PRIV, RIF_CID1, RIF_SEM_DIS, RIF_CFEN) /* Feature = CK_KER_ADC3 */
		RIFPROT(RIF_RCC_RESOURCE(48), EMPTY_SEMWL, RIF_UNLOCK, RIF_NSEC, RIF_PRIV, RIF_UNUSED, RIF_SEM_EN, RIF_CFEN) /* Feature = CK_KER_OSPI1 */
		RIFPROT(RIF_RCC_RESOURCE(49), RIF_UNUSED, RIF_UNLOCK, RIF_SEC, RIF_PRIV, RIF_CID1, RIF_SEM_DIS, RIF_CFEN) /* Feature = CK_KER_OSPI2 */
		RIFPROT(RIF_RCC_RESOURCE(50), EMPTY_SEMWL, RIF_UNLOCK, RIF_NSEC, RIF_PRIV, RIF_UNUSED, RIF_SEM_EN, RIF_CFEN) /* Feature = CK_KER_FMC */
		RIFPROT(RIF_RCC_RESOURCE(51), RIF_UNUSED, RIF_UNLOCK, RIF_SEC, RIF_PRIV, RIF_CID1, RIF_SEM_DIS, RIF_CFEN) /* Feature = CK_KER_SDMMC1 */
		RIFPROT(RIF_RCC_RESOURCE(52), EMPTY_SEMWL, RIF_UNLOCK, RIF_NSEC, RIF_PRIV, RIF_UNUSED, RIF_SEM_EN, RIF_CFEN) /* Feature = CK_KER_SDMMC2 */
		RIFPROT(RIF_RCC_RESOURCE(53), EMPTY_SEMWL, RIF_UNLOCK, RIF_NSEC, RIF_PRIV, RIF_UNUSED, RIF_SEM_EN, RIF_CFEN) /* Feature = CK_KER_SDMMC3 */
		RIFPROT(RIF_RCC_RESOURCE(54), RIF_UNUSED, RIF_UNLOCK, RIF_SEC, RIF_PRIV, RIF_CID1, RIF_SEM_DIS, RIF_CFEN) /* Feature = CK_KER_ETH1\nCK_KER_ETHSW */
		RIFPROT(RIF_RCC_RESOURCE(55), RIF_UNUSED, RIF_UNLOCK, RIF_SEC, RIF_PRIV, RIF_CID1, RIF_SEM_DIS, RIF_CFEN) /* Feature = CK_KER_ETH2 */
		RIFPROT(RIF_RCC_RESOURCE(56), RIF_UNUSED, RIF_UNLOCK, RIF_SEC, RIF_PRIV, RIF_CID1, RIF_SEM_DIS, RIF_CFEN) /* Feature = CK_KER_ETH1PTP\nCK_KER_ETH2PTP */
		RIFPROT(RIF_RCC_RESOURCE(57), RIF_UNUSED, RIF_UNLOCK, RIF_SEC, RIF_PRIV, RIF_CID1, RIF_SEM_DIS, RIF_CFEN) /* Feature = CK_KER_USB2PHY1 */
		RIFPROT(RIF_RCC_RESOURCE(58), RIF_UNUSED, RIF_UNLOCK, RIF_SEC, RIF_PRIV, RIF_CID1, RIF_SEM_DIS, RIF_CFEN) /* Feature = CK_KER_USB2PHY2 */
		RIFPROT(RIF_RCC_RESOURCE(59), RIF_UNUSED, RIF_UNLOCK, RIF_SEC, RIF_PRIV, RIF_CID1, RIF_SEM_DIS, RIF_CFEN) /* Feature = CK_ICN_M_GPU */
		RIFPROT(RIF_RCC_RESOURCE(60), RIF_UNUSED, RIF_UNLOCK, RIF_SEC, RIF_PRIV, RIF_CID1, RIF_SEM_DIS, RIF_CFEN) /* Feature = CK_KER_ETHSWREF */
		RIFPROT(RIF_RCC_RESOURCE(61), RIF_UNUSED, RIF_UNLOCK, RIF_SEC, RIF_PRIV, RIF_CID1, RIF_SEM_DIS, RIF_CFEN) /* Feature = CK_MCO1 */
		RIFPROT(RIF_RCC_RESOURCE(62), RIF_UNUSED, RIF_UNLOCK, RIF_SEC, RIF_PRIV, RIF_CID1, RIF_SEM_DIS, RIF_CFEN) /* Feature = CK_MCO2 */
		RIFPROT(RIF_RCC_RESOURCE(63), RIF_UNUSED, RIF_UNLOCK, RIF_SEC, RIF_PRIV, RIF_CID1, RIF_SEM_DIS, RIF_CFEN) /* Feature = CK_CPU1_EXT2F */
		RIFPROT(RIF_RCC_RESOURCE(64), RIF_UNUSED, RIF_UNLOCK, RIF_SEC, RIF_PRIV, RIF_CID1, RIF_SEM_DIS, RIF_CFEN) /* Feature = CK_SYS_PLL4,5,6,7,8 */
		RIFPROT(RIF_RCC_RESOURCE(65), RIF_UNUSED, RIF_UNLOCK, RIF_SEC, RIF_PRIV, RIF_CID1, RIF_SEM_DIS, RIF_CFEN) /* Feature = FCALC */
		RIFPROT(RIF_RCC_RESOURCE(66), RIF_UNUSED, RIF_UNLOCK, RIF_SEC, RIF_PRIV, RIF_CID1, RIF_SEM_DIS, RIF_CFEN) /* Feature = SYSRST */
		RIFPROT(RIF_RCC_RESOURCE(67), RIF_UNUSED, RIF_UNLOCK, RIF_SEC, RIF_PRIV, RIF_CID1, RIF_SEM_DIS, RIF_CFEN) /* Feature = BOOT_STDB */
		RIFPROT(RIF_RCC_RESOURCE(68), RIF_UNUSED, RIF_UNLOCK, RIF_SEC, RIF_PRIV, RIF_CID1, RIF_SEM_DIS, RIF_CFEN) /* Feature = RDCR */
		RIFPROT(RIF_RCC_RESOURCE(69), RIF_UNUSED, RIF_UNLOCK, RIF_SEC, RIF_PRIV, RIF_CID1, RIF_SEM_DIS, RIF_CFEN) /* Feature = SYSCLK */
		RIFPROT(RIF_RCC_RESOURCE(70), RIF_UNUSED, RIF_UNLOCK, RIF_SEC, RIF_PRIV, RIF_CID1, RIF_SEM_DIS, RIF_CFEN) /* Feature = CPU1_RES */
		RIFPROT(RIF_RCC_RESOURCE(71), RIF_CID1_BF|RIF_CID2_BF, RIF_UNLOCK, RIF_NSEC, RIF_PRIV, RIF_UNUSED, RIF_SEM_EN, RIF_CFEN) /* Feature = CPU2_RES */
		RIFPROT(RIF_RCC_RESOURCE(72), RIF_UNUSED, RIF_UNLOCK, RIF_SEC, RIF_PRIV, RIF_CID1, RIF_SEM_DIS, RIF_CFEN) /* Feature = CPU3_RES */
		RIFPROT(RIF_RCC_RESOURCE(73), RIF_UNUSED, RIF_UNLOCK, RIF_SEC, RIF_PRIV, RIF_CID1, RIF_SEM_DIS, RIF_CFEN) /* Feature = DEBUG_CFGR */
		RIFPROT(RIF_RCC_RESOURCE(74), RIF_UNUSED, RIF_UNLOCK, RIF_SEC, RIF_PRIV, RIF_CID1, RIF_SEM_DIS, RIF_CFEN) /* Feature = SYSRAM_CFGR */
		RIFPROT(RIF_RCC_RESOURCE(75), RIF_UNUSED, RIF_UNLOCK, RIF_SEC, RIF_PRIV, RIF_CID1, RIF_SEM_DIS, RIF_CFEN) /* Feature = VDERAM_CFGR */
		RIFPROT(RIF_RCC_RESOURCE(76), EMPTY_SEMWL, RIF_UNLOCK, RIF_NSEC, RIF_PRIV, RIF_UNUSED, RIF_SEM_EN, RIF_CFEN) /* Feature = RETRAM_CFGR */
		RIFPROT(RIF_RCC_RESOURCE(77), EMPTY_SEMWL, RIF_UNLOCK, RIF_NSEC, RIF_PRIV, RIF_UNUSED, RIF_SEM_EN, RIF_CFEN) /* Feature = BKPSRAM_CFGR */
		RIFPROT(RIF_RCC_RESOURCE(78), RIF_UNUSED, RIF_UNLOCK, RIF_SEC, RIF_PRIV, RIF_CID1, RIF_SEM_DIS, RIF_CFEN) /* Feature = SRAM1_CFGR */
		RIFPROT(RIF_RCC_RESOURCE(79), RIF_UNUSED, RIF_UNLOCK, RIF_SEC, RIF_PRIV, RIF_CID1, RIF_SEM_DIS, RIF_CFEN) /* Feature = SRAM2_CFGR */
		RIFPROT(RIF_RCC_RESOURCE(80), RIF_UNUSED, RIF_UNLOCK, RIF_SEC, RIF_PRIV, RIF_CID1, RIF_SEM_DIS, RIF_CFEN) /* Feature = LPSRAM1_CFGR */
		RIFPROT(RIF_RCC_RESOURCE(81), RIF_UNUSED, RIF_UNLOCK, RIF_SEC, RIF_PRIV, RIF_CID1, RIF_SEM_DIS, RIF_CFEN) /* Feature = LPSRAM2_CFGR */
		RIFPROT(RIF_RCC_RESOURCE(82), RIF_UNUSED, RIF_UNLOCK, RIF_SEC, RIF_PRIV, RIF_CID1, RIF_SEM_DIS, RIF_CFEN) /* Feature = LPSRAM3_CFGR */
		RIFPROT(RIF_RCC_RESOURCE(83), RIF_UNUSED, RIF_UNLOCK, RIF_SEC, RIF_PRIV, RIF_CID1, RIF_SEM_DIS, RIF_CFEN) /* Feature = HPDMA1_CFGR */
		RIFPROT(RIF_RCC_RESOURCE(84), RIF_UNUSED, RIF_UNLOCK, RIF_SEC, RIF_PRIV, RIF_CID1, RIF_SEM_DIS, RIF_CFEN) /* Feature = HPDMA2_CFGR */
		RIFPROT(RIF_RCC_RESOURCE(85), RIF_UNUSED, RIF_UNLOCK, RIF_SEC, RIF_PRIV, RIF_CID2, RIF_SEM_DIS, RIF_CFEN) /* Feature = HPDMA3_CFGR */
		RIFPROT(RIF_RCC_RESOURCE(86), EMPTY_SEMWL, RIF_UNLOCK, RIF_NSEC, RIF_NPRIV, RIF_UNUSED, RIF_SEM_EN, RIF_CFEN) /* Feature = LPDMA_CFGR */
		RIFPROT(RIF_RCC_RESOURCE(87), EMPTY_SEMWL, RIF_UNLOCK, RIF_NSEC, RIF_NPRIV, RIF_UNUSED, RIF_SEM_EN, RIF_CFEN) /* Feature = IPCC1_CFGR */
		RIFPROT(RIF_RCC_RESOURCE(88), EMPTY_SEMWL, RIF_UNLOCK, RIF_NSEC, RIF_NPRIV, RIF_UNUSED, RIF_SEM_EN, RIF_CFEN) /* Feature = IPCC2_CFGR */
		RIFPROT(RIF_RCC_RESOURCE(89), EMPTY_SEMWL, RIF_UNLOCK, RIF_NSEC, RIF_NPRIV, RIF_UNUSED, RIF_SEM_EN, RIF_CFEN) /* Feature = HSEM_CFGR */
		RIFPROT(RIF_RCC_RESOURCE(90), RIF_UNUSED, RIF_UNLOCK, RIF_NSEC, RIF_NPRIV, RIF_CID1, RIF_SEM_DIS, RIF_CFEN) /* Feature = GPIOA_CFGR */
		RIFPROT(RIF_RCC_RESOURCE(91), RIF_UNUSED, RIF_UNLOCK, RIF_NSEC, RIF_NPRIV, RIF_CID1, RIF_SEM_DIS, RIF_CFEN) /* Feature = GPIOB_CFGR */
		RIFPROT(RIF_RCC_RESOURCE(92), RIF_UNUSED, RIF_UNLOCK, RIF_NSEC, RIF_NPRIV, RIF_CID1, RIF_SEM_DIS, RIF_CFEN) /* Feature = GPIOC_CFGR */
		RIFPROT(RIF_RCC_RESOURCE(93), RIF_UNUSED, RIF_UNLOCK, RIF_NSEC, RIF_NPRIV, RIF_CID1, RIF_SEM_DIS, RIF_CFEN) /* Feature = GPIOD_CFGR */
		RIFPROT(RIF_RCC_RESOURCE(94), RIF_UNUSED, RIF_UNLOCK, RIF_NSEC, RIF_NPRIV, RIF_CID1, RIF_SEM_DIS, RIF_CFEN) /* Feature = GPIOE_CFGR */
		RIFPROT(RIF_RCC_RESOURCE(95), RIF_CID1_BF, RIF_UNLOCK, RIF_NSEC, RIF_NPRIV, RIF_UNUSED, RIF_SEM_EN, RIF_CFEN) /* Feature = GPIOF_CFGR */
		RIFPROT(RIF_RCC_RESOURCE(96), RIF_CID1_BF, RIF_UNLOCK, RIF_NSEC, RIF_NPRIV, RIF_UNUSED, RIF_SEM_EN, RIF_CFEN) /* Feature = GPIOG_CFGR */
		RIFPROT(RIF_RCC_RESOURCE(97), RIF_UNUSED, RIF_UNLOCK, RIF_NSEC, RIF_NPRIV, RIF_CID1, RIF_SEM_DIS, RIF_CFEN) /* Feature = GPIOH_CFGR */
		RIFPROT(RIF_RCC_RESOURCE(98), RIF_CID1_BF, RIF_UNLOCK, RIF_NSEC, RIF_NPRIV, RIF_UNUSED, RIF_SEM_EN, RIF_CFEN) /* Feature = GPIOI_CFGR */
		RIFPROT(RIF_RCC_RESOURCE(99), RIF_CID1_BF, RIF_UNLOCK, RIF_NSEC, RIF_NPRIV, RIF_UNUSED, RIF_SEM_EN, RIF_CFEN) /* Feature = GPIOJ_CFGR */
		RIFPROT(RIF_RCC_RESOURCE(100), RIF_UNUSED, RIF_UNLOCK, RIF_NSEC, RIF_PRIV, RIF_CID1, RIF_SEM_DIS, RIF_CFEN) /* Feature = GPIOK_CFGR */
		RIFPROT(RIF_RCC_RESOURCE(101), RIF_UNUSED, RIF_UNLOCK, RIF_NSEC, RIF_PRIV, RIF_CID1, RIF_SEM_DIS, RIF_CFEN) /* Feature = GPIOZ_CFGR */
		RIFPROT(RIF_RCC_RESOURCE(102), RIF_UNUSED, RIF_UNLOCK, RIF_NSEC, RIF_PRIV, RIF_CID1, RIF_SEM_DIS, RIF_CFEN) /* Feature = RTC_CFGR */
		RIFPROT(RIF_RCC_RESOURCE(103), RIF_UNUSED, RIF_UNLOCK, RIF_SEC, RIF_NPRIV, RIF_CID1, RIF_SEM_DIS, RIF_CFEN) /* Feature = BSEC_CFGR */
		RIFPROT(RIF_RCC_RESOURCE(104), RIF_UNUSED, RIF_UNLOCK, RIF_SEC, RIF_NPRIV, RIF_CID1, RIF_SEM_DIS, RIF_CFEN) /* Feature = DDRC_CFGR */
		RIFPROT(RIF_RCC_RESOURCE(105), RIF_UNUSED, RIF_UNLOCK, RIF_SEC, RIF_NPRIV, RIF_CID1, RIF_SEM_DIS, RIF_CFEN) /* Feature = PLL3_CFGR */
		RIFPROT(RIF_RCC_RESOURCE(106), RIF_UNUSED, RIF_UNLOCK, RIF_SEC, RIF_NPRIV, RIF_CID1, RIF_SEM_DIS, RIF_CFEN) /* Feature = SYSCPU1_CFGR */
		RIFPROT(RIF_RCC_RESOURCE(108), RIF_UNUSED, RIF_UNLOCK, RIF_SEC, RIF_NPRIV, RIF_CID1, RIF_SEM_DIS, RIF_CFEN) /* Feature = MCO1_CFGR */
		RIFPROT(RIF_RCC_RESOURCE(109), RIF_UNUSED, RIF_UNLOCK, RIF_SEC, RIF_NPRIV, RIF_CID1, RIF_SEM_DIS, RIF_CFEN) /* Feature = MCO2_CFGR */
		RIFPROT(RIF_RCC_RESOURCE(110), EMPTY_SEMWL, RIF_UNLOCK, RIF_NSEC, RIF_NPRIV, RIF_UNUSED, RIF_SEM_EN, RIF_CFEN) /* Feature = OSPI1_CFGR */
		RIFPROT(RIF_RCC_RESOURCE(111), EMPTY_SEMWL, RIF_UNLOCK, RIF_NSEC, RIF_NPRIV, RIF_UNUSED, RIF_SEM_EN, RIF_CFEN) /* Feature = OSPI2_CFGR */
		RIFPROT(RIF_RCC_RESOURCE(112), EMPTY_SEMWL, RIF_UNLOCK, RIF_NSEC, RIF_NPRIV, RIF_UNUSED, RIF_SEM_EN, RIF_CFEN) /* Feature = FMC_CFGR */
		RIFPROT(RIF_RCC_RESOURCE(113), RIF_UNUSED, RIF_UNLOCK, RIF_SEC, RIF_NPRIV, RIF_CID1, RIF_SEM_DIS, RIF_CFEN) /* Feature = HSI_MON */
	>;
};

&pwr{

	st,protreg = <
		RIFPROT(RIF_PWR_RESOURCE(0), RIF_UNUSED, RIF_UNLOCK, RIF_SEC, RIF_PRIV, RIF_CID1, RIF_SEM_DIS, RIF_CFEN) /* Feature = Voltage monitoring */
		RIFPROT(RIF_PWR_RESOURCE(1), RIF_UNUSED, RIF_UNLOCK, RIF_SEC, RIF_PRIV, RIF_CID1, RIF_SEM_DIS, RIF_CFEN) /* Feature = RAM and low power */
		RIFPROT(RIF_PWR_RESOURCE(2), RIF_UNUSED, RIF_UNLOCK, RIF_SEC, RIF_PRIV, RIF_CID1, RIF_SEM_DIS, RIF_CFEN) /* Feature = CPU1 power control */
		RIFPROT(RIF_PWR_RESOURCE(3), RIF_UNUSED, RIF_UNLOCK, RIF_SEC, RIF_PRIV, RIF_CID1, RIF_SEM_DIS, RIF_CFEN) /* Feature = CPU2 power control */
		RIFPROT(RIF_PWR_RESOURCE(4), RIF_UNUSED, RIF_UNLOCK, RIF_SEC, RIF_PRIV, RIF_CID1, RIF_SEM_DIS, RIF_CFEN) /* Feature = CPU3 power control */
		RIFPROT(RIF_PWR_RESOURCE(5), RIF_UNUSED, RIF_UNLOCK, RIF_SEC, RIF_PRIV, RIF_CID1, RIF_SEM_DIS, RIF_CFEN) /* Feature = VDD eMMC */
		RIFPROT(RIF_PWR_RESOURCE(6), RIF_UNUSED, RIF_UNLOCK, RIF_SEC, RIF_PRIV, RIF_CID1, RIF_SEM_DIS, RIF_CFEN) /* Feature = VDD SD */
		RIFPROT(RIF_PWR_RESOURCE_WIO(1), RIF_UNUSED, RIF_UNLOCK, RIF_NSEC, RIF_PRIV, RIF_CID1, RIF_SEM_DIS, RIF_CFEN) /* Feature = Wake up 1 */
		RIFPROT(RIF_PWR_RESOURCE_WIO(2), RIF_UNUSED, RIF_UNLOCK, RIF_NSEC, RIF_PRIV, RIF_CID1, RIF_SEM_DIS, RIF_CFEN) /* Feature = Wake up 2 */
		RIFPROT(RIF_PWR_RESOURCE_WIO(3), RIF_UNUSED, RIF_UNLOCK, RIF_NSEC, RIF_NPRIV, RIF_CID2, RIF_SEM_DIS, RIF_CFEN) /* Feature = Wake up 3 */
		RIFPROT(RIF_PWR_RESOURCE_WIO(4), EMPTY_SEMWL, RIF_UNLOCK, RIF_NSEC, RIF_NPRIV, RIF_UNUSED, RIF_SEM_EN, RIF_CFEN) /* Feature = Wake up 4 */
		RIFPROT(RIF_PWR_RESOURCE_WIO(5), EMPTY_SEMWL, RIF_UNLOCK, RIF_NSEC, RIF_NPRIV, RIF_UNUSED, RIF_SEM_EN, RIF_CFEN) /* Feature = Wake up 5 */
		RIFPROT(RIF_PWR_RESOURCE_WIO(6), EMPTY_SEMWL, RIF_UNLOCK, RIF_NSEC, RIF_NPRIV, RIF_UNUSED, RIF_SEM_EN, RIF_CFEN) /* Feature = Wake up 6 */
	>;
};

&hsem{

	st,protreg = <
		RIFPROT(RIF_HSEM_RESOURCE(0), RIF_UNUSED, RIF_UNLOCK, RIF_NSEC, RIF_NPRIV, RIF_UNUSED, RIF_SEM_DIS, RIF_CFDIS) /* Feature = Group 0 Semaphore 0 */
		RIFPROT(RIF_HSEM_RESOURCE(1), RIF_UNUSED, RIF_UNLOCK, RIF_NSEC, RIF_NPRIV, RIF_UNUSED, RIF_SEM_DIS, RIF_CFDIS) /* Feature = Group 0 Semaphore 1 */
		RIFPROT(RIF_HSEM_RESOURCE(2), RIF_UNUSED, RIF_UNLOCK, RIF_NSEC, RIF_NPRIV, RIF_UNUSED, RIF_SEM_DIS, RIF_CFDIS) /* Feature = Group 0 Semaphore 2 */
		RIFPROT(RIF_HSEM_RESOURCE(3), RIF_UNUSED, RIF_UNLOCK, RIF_NSEC, RIF_NPRIV, RIF_UNUSED, RIF_SEM_DIS, RIF_CFDIS) /* Feature = Group 0 Semaphore 3 */
		RIFPROT(RIF_HSEM_RESOURCE(4), RIF_UNUSED, RIF_UNLOCK, RIF_NSEC, RIF_NPRIV, RIF_UNUSED, RIF_SEM_DIS, RIF_CFDIS) /* Feature = Group 1 Semaphore 4 */
		RIFPROT(RIF_HSEM_RESOURCE(5), RIF_UNUSED, RIF_UNLOCK, RIF_NSEC, RIF_NPRIV, RIF_UNUSED, RIF_SEM_DIS, RIF_CFDIS) /* Feature = Group 1 Semaphore 5 */
		RIFPROT(RIF_HSEM_RESOURCE(6), RIF_UNUSED, RIF_UNLOCK, RIF_NSEC, RIF_NPRIV, RIF_UNUSED, RIF_SEM_DIS, RIF_CFDIS) /* Feature = Group 1 Semaphore 6 */
		RIFPROT(RIF_HSEM_RESOURCE(7), RIF_UNUSED, RIF_UNLOCK, RIF_NSEC, RIF_NPRIV, RIF_UNUSED, RIF_SEM_DIS, RIF_CFDIS) /* Feature = Group 1 Semaphore 7 */
		RIFPROT(RIF_HSEM_RESOURCE(8), RIF_UNUSED, RIF_UNLOCK, RIF_NSEC, RIF_NPRIV, RIF_UNUSED, RIF_SEM_DIS, RIF_CFDIS) /* Feature = Group 2 Semaphore 8 */
		RIFPROT(RIF_HSEM_RESOURCE(9), RIF_UNUSED, RIF_UNLOCK, RIF_NSEC, RIF_NPRIV, RIF_UNUSED, RIF_SEM_DIS, RIF_CFDIS) /* Feature = Group 2 Semaphore 9 */
		RIFPROT(RIF_HSEM_RESOURCE(10), RIF_UNUSED, RIF_UNLOCK, RIF_NSEC, RIF_NPRIV, RIF_UNUSED, RIF_SEM_DIS, RIF_CFDIS) /* Feature = Group 2 Semaphore 10 */
		RIFPROT(RIF_HSEM_RESOURCE(11), RIF_UNUSED, RIF_UNLOCK, RIF_NSEC, RIF_NPRIV, RIF_UNUSED, RIF_SEM_DIS, RIF_CFDIS) /* Feature = Group 2 Semaphore 11 */
		RIFPROT(RIF_HSEM_RESOURCE(12), RIF_UNUSED, RIF_UNLOCK, RIF_NSEC, RIF_NPRIV, RIF_UNUSED, RIF_SEM_DIS, RIF_CFDIS) /* Feature = Group 3 Semaphore 12 */
		RIFPROT(RIF_HSEM_RESOURCE(13), RIF_UNUSED, RIF_UNLOCK, RIF_NSEC, RIF_NPRIV, RIF_UNUSED, RIF_SEM_DIS, RIF_CFDIS) /* Feature = Group 3 Semaphore 13 */
		RIFPROT(RIF_HSEM_RESOURCE(14), RIF_UNUSED, RIF_UNLOCK, RIF_NSEC, RIF_NPRIV, RIF_UNUSED, RIF_SEM_DIS, RIF_CFDIS) /* Feature = Group 3 Semaphore 14 */
		RIFPROT(RIF_HSEM_RESOURCE(15), RIF_UNUSED, RIF_UNLOCK, RIF_NSEC, RIF_NPRIV, RIF_UNUSED, RIF_SEM_DIS, RIF_CFDIS) /* Feature = Group 3 Semaphore 15 */
	>;
	st,proccid = <1 RIF_CID1>, <2 RIF_CID2>;
};

&exti2{

	st,protreg = <
		RIFPROT(RIF_EXTI2_RESOURCE(0), RIF_UNUSED, RIF_UNLOCK, RIF_NSEC, RIF_NPRIV, RIF_UNUSED, RIF_SEM_DIS, RIF_CFDIS) /* Feature = EXTI2[0] */
		RIFPROT(RIF_EXTI2_RESOURCE(1), RIF_UNUSED, RIF_UNLOCK, RIF_NSEC, RIF_NPRIV, RIF_UNUSED, RIF_SEM_DIS, RIF_CFDIS) /* Feature = EXTI2[1] */
		RIFPROT(RIF_EXTI2_RESOURCE(2), RIF_UNUSED, RIF_UNLOCK, RIF_NSEC, RIF_PRIV, RIF_UNUSED, RIF_SEM_DIS, RIF_CFDIS) /* Feature = EXTI2[2] */
		RIFPROT(RIF_EXTI2_RESOURCE(3), RIF_UNUSED, RIF_UNLOCK, RIF_NSEC, RIF_NPRIV, RIF_UNUSED, RIF_SEM_DIS, RIF_CFDIS) /* Feature = EXTI2[3] */
		RIFPROT(RIF_EXTI2_RESOURCE(4), RIF_UNUSED, RIF_UNLOCK, RIF_NSEC, RIF_NPRIV, RIF_UNUSED, RIF_SEM_DIS, RIF_CFDIS) /* Feature = EXTI2[4] */
		RIFPROT(RIF_EXTI2_RESOURCE(5), RIF_UNUSED, RIF_UNLOCK, RIF_NSEC, RIF_NPRIV, RIF_UNUSED, RIF_SEM_DIS, RIF_CFDIS) /* Feature = EXTI2[5] */
		RIFPROT(RIF_EXTI2_RESOURCE(6), RIF_UNUSED, RIF_UNLOCK, RIF_NSEC, RIF_NPRIV, RIF_UNUSED, RIF_SEM_DIS, RIF_CFDIS) /* Feature = EXTI2[6] */
		RIFPROT(RIF_EXTI2_RESOURCE(7), RIF_UNUSED, RIF_UNLOCK, RIF_NSEC, RIF_NPRIV, RIF_UNUSED, RIF_SEM_DIS, RIF_CFDIS) /* Feature = EXTI2[7] */
		RIFPROT(RIF_EXTI2_RESOURCE(8), RIF_UNUSED, RIF_UNLOCK, RIF_NSEC, RIF_NPRIV, RIF_UNUSED, RIF_SEM_DIS, RIF_CFDIS) /* Feature = EXTI2[8] */
		RIFPROT(RIF_EXTI2_RESOURCE(9), RIF_UNUSED, RIF_UNLOCK, RIF_NSEC, RIF_NPRIV, RIF_UNUSED, RIF_SEM_DIS, RIF_CFDIS) /* Feature = EXTI2[9] */
		RIFPROT(RIF_EXTI2_RESOURCE(10), RIF_UNUSED, RIF_UNLOCK, RIF_NSEC, RIF_NPRIV, RIF_UNUSED, RIF_SEM_DIS, RIF_CFDIS) /* Feature = EXTI2[10] */
		RIFPROT(RIF_EXTI2_RESOURCE(11), RIF_UNUSED, RIF_UNLOCK, RIF_NSEC, RIF_NPRIV, RIF_UNUSED, RIF_SEM_DIS, RIF_CFDIS) /* Feature = EXTI2[11] */
		RIFPROT(RIF_EXTI2_RESOURCE(12), RIF_UNUSED, RIF_UNLOCK, RIF_NSEC, RIF_NPRIV, RIF_UNUSED, RIF_SEM_DIS, RIF_CFDIS) /* Feature = EXTI2[12] */
		RIFPROT(RIF_EXTI2_RESOURCE(13), RIF_UNUSED, RIF_UNLOCK, RIF_NSEC, RIF_NPRIV, RIF_UNUSED, RIF_SEM_DIS, RIF_CFDIS) /* Feature = EXTI2[13] */
		RIFPROT(RIF_EXTI2_RESOURCE(14), RIF_UNUSED, RIF_UNLOCK, RIF_NSEC, RIF_NPRIV, RIF_UNUSED, RIF_SEM_DIS, RIF_CFDIS) /* Feature = EXTI2[14] */
		RIFPROT(RIF_EXTI2_RESOURCE(15), RIF_UNUSED, RIF_UNLOCK, RIF_NSEC, RIF_NPRIV, RIF_UNUSED, RIF_SEM_DIS, RIF_CFDIS) /* Feature = EXTI2[15] */
		RIFPROT(RIF_EXTI2_RESOURCE(16), RIF_UNUSED, RIF_UNLOCK, RIF_NSEC, RIF_PRIV, RIF_UNUSED, RIF_SEM_DIS, RIF_CFDIS) /* Feature = TAMP non secure tamper CPU1 */
		RIFPROT(RIF_EXTI2_RESOURCE(17), RIF_UNUSED, RIF_UNLOCK, RIF_NSEC, RIF_PRIV, RIF_UNUSED, RIF_SEM_DIS, RIF_CFDIS) /* Feature = RTC global non secure Wakeup CPU1 */
		RIFPROT(RIF_EXTI2_RESOURCE(18), RIF_UNUSED, RIF_UNLOCK, RIF_NSEC, RIF_NPRIV, RIF_UNUSED, RIF_SEM_DIS, RIF_CFDIS) /* Feature = TAMP non secure tamper CPU2 */
		RIFPROT(RIF_EXTI2_RESOURCE(19), RIF_UNUSED, RIF_UNLOCK, RIF_NSEC, RIF_NPRIV, RIF_UNUSED, RIF_SEM_DIS, RIF_CFDIS) /* Feature = RTC global non secure Wakeup CPU2 */
		RIFPROT(RIF_EXTI2_RESOURCE(20), RIF_UNUSED, RIF_UNLOCK, RIF_NSEC, RIF_NPRIV, RIF_UNUSED, RIF_SEM_DIS, RIF_CFDIS) /* Feature = TAMP non secure tamper CPU3 */
		RIFPROT(RIF_EXTI2_RESOURCE(21), RIF_UNUSED, RIF_UNLOCK, RIF_NSEC, RIF_PRIV, RIF_UNUSED, RIF_SEM_DIS, RIF_CFDIS) /* Feature = TAMP secure tamper CPU1 */
		RIFPROT(RIF_EXTI2_RESOURCE(22), RIF_UNUSED, RIF_UNLOCK, RIF_NSEC, RIF_PRIV, RIF_UNUSED, RIF_SEM_DIS, RIF_CFDIS) /* Feature = RTC global secure Wakeup CPU1 */
		RIFPROT(RIF_EXTI2_RESOURCE(23), RIF_UNUSED, RIF_UNLOCK, RIF_NSEC, RIF_PRIV, RIF_UNUSED, RIF_SEM_DIS, RIF_CFDIS) /* Feature = TAMP secure tamper CPU2 */
		RIFPROT(RIF_EXTI2_RESOURCE(24), RIF_UNUSED, RIF_UNLOCK, RIF_NSEC, RIF_PRIV, RIF_UNUSED, RIF_SEM_DIS, RIF_CFDIS) /* Feature = RTC global secure Wakeup CPU2 */
		RIFPROT(RIF_EXTI2_RESOURCE(25), RIF_UNUSED, RIF_UNLOCK, RIF_NSEC, RIF_PRIV, RIF_UNUSED, RIF_SEM_DIS, RIF_CFDIS) /* Feature = I2C8 */
		RIFPROT(RIF_EXTI2_RESOURCE(26), RIF_UNUSED, RIF_UNLOCK, RIF_NSEC, RIF_NPRIV, RIF_UNUSED, RIF_SEM_DIS, RIF_CFDIS) /* Feature = LPUART1 */
		RIFPROT(RIF_EXTI2_RESOURCE(27), RIF_UNUSED, RIF_UNLOCK, RIF_NSEC, RIF_PRIV, RIF_UNUSED, RIF_SEM_DIS, RIF_CFDIS) /* Feature = SPI8 */
		RIFPROT(RIF_EXTI2_RESOURCE(29), RIF_UNUSED, RIF_UNLOCK, RIF_NSEC, RIF_PRIV, RIF_UNUSED, RIF_SEM_DIS, RIF_CFDIS) /* Feature = LPTIM3 */
		RIFPROT(RIF_EXTI2_RESOURCE(30), RIF_UNUSED, RIF_UNLOCK, RIF_NSEC, RIF_PRIV, RIF_UNUSED, RIF_SEM_DIS, RIF_CFDIS) /* Feature = LPTIM4 */
		RIFPROT(RIF_EXTI2_RESOURCE(31), RIF_UNUSED, RIF_UNLOCK, RIF_NSEC, RIF_PRIV, RIF_UNUSED, RIF_SEM_DIS, RIF_CFDIS) /* Feature = LPTIM5 */
		RIFPROT(RIF_EXTI2_RESOURCE(33), RIF_UNUSED, RIF_UNLOCK, RIF_NSEC, RIF_NPRIV, RIF_UNUSED, RIF_SEM_DIS, RIF_CFDIS) /* Feature = ADF1 */
		RIFPROT(RIF_EXTI2_RESOURCE(34), RIF_UNUSED, RIF_UNLOCK, RIF_NSEC, RIF_PRIV, RIF_UNUSED, RIF_SEM_DIS, RIF_CFDIS) /* Feature = IPCC2 non secure interrupt CPU1 */
		RIFPROT(RIF_EXTI2_RESOURCE(35), RIF_UNUSED, RIF_UNLOCK, RIF_NSEC, RIF_NPRIV, RIF_UNUSED, RIF_SEM_DIS, RIF_CFDIS) /* Feature = IPCC2 non secure interrupt CPU2 */
		RIFPROT(RIF_EXTI2_RESOURCE(36), RIF_UNUSED, RIF_UNLOCK, RIF_NSEC, RIF_NPRIV, RIF_UNUSED, RIF_SEM_DIS, RIF_CFDIS) /* Feature = IPCC2 non secure interrupt CPU3 */
		RIFPROT(RIF_EXTI2_RESOURCE(37), RIF_UNUSED, RIF_UNLOCK, RIF_NSEC, RIF_PRIV, RIF_UNUSED, RIF_SEM_DIS, RIF_CFDIS) /* Feature = IPCC2 secure interrupt CPU1 */
		RIFPROT(RIF_EXTI2_RESOURCE(38), RIF_UNUSED, RIF_UNLOCK, RIF_NSEC, RIF_PRIV, RIF_UNUSED, RIF_SEM_DIS, RIF_CFDIS) /* Feature = IPCC2 secure interrupt CPU2 */
		RIFPROT(RIF_EXTI2_RESOURCE(40), RIF_UNUSED, RIF_UNLOCK, RIF_NSEC, RIF_NPRIV, RIF_UNUSED, RIF_SEM_DIS, RIF_CFDIS) /* Feature = HSEM1 non secure interrupt */
		RIFPROT(RIF_EXTI2_RESOURCE(41), RIF_UNUSED, RIF_UNLOCK, RIF_NSEC, RIF_NPRIV, RIF_UNUSED, RIF_SEM_DIS, RIF_CFDIS) /* Feature = HSEM2 non secure interrupt */
		RIFPROT(RIF_EXTI2_RESOURCE(42), RIF_UNUSED, RIF_UNLOCK, RIF_NSEC, RIF_NPRIV, RIF_UNUSED, RIF_SEM_DIS, RIF_CFDIS) /* Feature = HSEM3 non secure interrupt */
		RIFPROT(RIF_EXTI2_RESOURCE(43), RIF_UNUSED, RIF_UNLOCK, RIF_NSEC, RIF_NPRIV, RIF_UNUSED, RIF_SEM_DIS, RIF_CFDIS) /* Feature = HSEM1 secure interrupt */
		RIFPROT(RIF_EXTI2_RESOURCE(44), RIF_UNUSED, RIF_UNLOCK, RIF_NSEC, RIF_NPRIV, RIF_UNUSED, RIF_SEM_DIS, RIF_CFDIS) /* Feature = HSEM2 secure interrupt */
		RIFPROT(RIF_EXTI2_RESOURCE(46), RIF_UNUSED, RIF_UNLOCK, RIF_NSEC, RIF_NPRIV, RIF_UNUSED, RIF_SEM_DIS, RIF_CFDIS) /* Feature = WWDG2 reset */
		RIFPROT(RIF_EXTI2_RESOURCE(47), RIF_UNUSED, RIF_UNLOCK, RIF_NSEC, RIF_PRIV, RIF_UNUSED, RIF_SEM_DIS, RIF_CFDIS) /* Feature = IWDG1 reset */
		RIFPROT(RIF_EXTI2_RESOURCE(48), RIF_UNUSED, RIF_UNLOCK, RIF_NSEC, RIF_PRIV, RIF_CID1, RIF_SEM_DIS, RIF_CFEN) /* Feature = IWDG2 reset */
		RIFPROT(RIF_EXTI2_RESOURCE(49), RIF_UNUSED, RIF_UNLOCK, RIF_NSEC, RIF_PRIV, RIF_UNUSED, RIF_SEM_DIS, RIF_CFDIS) /* Feature = IWDG3 reset */
		RIFPROT(RIF_EXTI2_RESOURCE(50), RIF_UNUSED, RIF_UNLOCK, RIF_NSEC, RIF_NPRIV, RIF_CID2, RIF_SEM_DIS, RIF_CFEN) /* Feature = IWDG4 reset */
		RIFPROT(RIF_EXTI2_RESOURCE(51), RIF_UNUSED, RIF_UNLOCK, RIF_NSEC, RIF_NPRIV, RIF_UNUSED, RIF_SEM_DIS, RIF_CFDIS) /* Feature = IWDG5 reset */
		RIFPROT(RIF_EXTI2_RESOURCE(52), RIF_UNUSED, RIF_UNLOCK, RIF_SEC, RIF_PRIV, RIF_CID1, RIF_SEM_DIS, RIF_CFEN) /* Feature = IWDG1 early wake */
		RIFPROT(RIF_EXTI2_RESOURCE(53), RIF_UNUSED, RIF_UNLOCK, RIF_NSEC, RIF_PRIV, RIF_UNUSED, RIF_SEM_DIS, RIF_CFDIS) /* Feature = IWDG2 early wake */
		RIFPROT(RIF_EXTI2_RESOURCE(54), RIF_UNUSED, RIF_UNLOCK, RIF_NSEC, RIF_PRIV, RIF_UNUSED, RIF_SEM_DIS, RIF_CFDIS) /* Feature = IWDG3 early wake */
		RIFPROT(RIF_EXTI2_RESOURCE(55), RIF_UNUSED, RIF_UNLOCK, RIF_NSEC, RIF_NPRIV, RIF_UNUSED, RIF_SEM_DIS, RIF_CFDIS) /* Feature = IWDG4 early wake */
		RIFPROT(RIF_EXTI2_RESOURCE(56), RIF_UNUSED, RIF_UNLOCK, RIF_NSEC, RIF_NPRIV, RIF_UNUSED, RIF_SEM_DIS, RIF_CFDIS) /* Feature = IWDG5 early wake */
		RIFPROT(RIF_EXTI2_RESOURCE(59), RIF_UNUSED, RIF_UNLOCK, RIF_NSEC, RIF_NPRIV, RIF_UNUSED, RIF_SEM_DIS, RIF_CFDIS) /* Feature = CM33 SEV interrupt to CPU3 */
		RIFPROT(RIF_EXTI2_RESOURCE(60), RIF_UNUSED, RIF_UNLOCK, RIF_NSEC, RIF_NPRIV, RIF_UNUSED, RIF_SEM_DIS, RIF_CFDIS) /* Feature = CA35 SEV interrupt to CPU3 */
		RIFPROT(RIF_EXTI2_RESOURCE(61), RIF_UNUSED, RIF_UNLOCK, RIF_NSEC, RIF_PRIV, RIF_CID1, RIF_SEM_DIS, RIF_CFEN) /* Feature = CM0 SEV interrupt */
		RIFPROT(RIF_EXTI2_RESOURCE(62), RIF_UNUSED, RIF_UNLOCK, RIF_NSEC, RIF_PRIV, RIF_UNUSED, RIF_SEM_DIS, RIF_CFDIS) /* Feature = IAC interrupt CPU1 */
		RIFPROT(RIF_EXTI2_RESOURCE(62), RIF_UNUSED, RIF_UNLOCK, RIF_NSEC, RIF_PRIV, RIF_UNUSED, RIF_SEM_DIS, RIF_CFDIS) /* Feature = IAC interrupt CPU2 */
		RIFPROT(RIF_EXTI2_RESOURCE(64), RIF_UNUSED, RIF_UNLOCK, RIF_NSEC, RIF_PRIV, RIF_UNUSED, RIF_SEM_DIS, RIF_CFDIS) /* Feature = VDDCPU_VD */
		RIFPROT(RIF_EXTI2_RESOURCE(65), RIF_UNUSED, RIF_UNLOCK, RIF_NSEC, RIF_PRIV, RIF_UNUSED, RIF_SEM_DIS, RIF_CFDIS) /* Feature = VDDCORE_VD */
		RIFPROT(RIF_EXTI2_RESOURCE(66), RIF_UNUSED, RIF_UNLOCK, RIF_NSEC, RIF_PRIV, RIF_UNUSED, RIF_SEM_DIS, RIF_CFDIS) /* Feature = RETRAM CRC error wakeup */
		RIFPROT(RIF_EXTI2_RESOURCE(67), RIF_UNUSED, RIF_UNLOCK, RIF_NSEC, RIF_PRIV, RIF_CID1, RIF_SEM_DIS, RIF_CFEN) /* Feature = lpdma1_ch0123_CPU1_irq */
		RIFPROT(RIF_EXTI2_RESOURCE(68), RIF_UNUSED, RIF_UNLOCK, RIF_NSEC, RIF_PRIV, RIF_CID2, RIF_SEM_DIS, RIF_CFEN) /* Feature = lpdma1_ch0123_CPU2_irq */
		RIFPROT(RIF_EXTI2_RESOURCE(69), RIF_UNUSED, RIF_UNLOCK, RIF_NSEC, RIF_NPRIV, RIF_UNUSED, RIF_SEM_DIS, RIF_CFDIS) /* Feature = lpdma1_ch0123_CPU3_irq */
		RIFPROT(RIF_EXTI2_RESOURCE(70), RIF_UNUSED, RIF_UNLOCK, RIF_NSEC, RIF_NPRIV, RIF_UNUSED, RIF_SEM_DIS, RIF_CFDIS) /* Feature = I3C4 */
		RIFPROT(RIF_EXTI2_RESOURCE(76), RIF_UNUSED, RIF_UNLOCK, RIF_NSEC, RIF_NPRIV, RIF_UNUSED, RIF_SEM_DIS, RIF_CFDIS) /* Feature = CDBGPWRUPREQ */
	>;
	st,proccid = <1 RIF_CID1>, <2 RIF_CID2>;
};

&exti1{

	st,protreg = <
		RIFPROT(RIF_EXTI1_RESOURCE(0), RIF_UNUSED, RIF_UNLOCK, RIF_NSEC, RIF_NPRIV, RIF_UNUSED, RIF_SEM_DIS, RIF_CFDIS) /* Feature = EXTI1[0] */
		RIFPROT(RIF_EXTI1_RESOURCE(1), RIF_UNUSED, RIF_UNLOCK, RIF_NSEC, RIF_NPRIV, RIF_UNUSED, RIF_SEM_DIS, RIF_CFDIS) /* Feature = EXTI1[1] */
		RIFPROT(RIF_EXTI1_RESOURCE(2), RIF_UNUSED, RIF_UNLOCK, RIF_NSEC, RIF_PRIV, RIF_UNUSED, RIF_SEM_DIS, RIF_CFDIS) /* Feature = EXTI1[2] */
		RIFPROT(RIF_EXTI1_RESOURCE(3), RIF_UNUSED, RIF_UNLOCK, RIF_NSEC, RIF_PRIV, RIF_CID1, RIF_SEM_DIS, RIF_CFEN) /* Feature = EXTI1[3] */
		RIFPROT(RIF_EXTI1_RESOURCE(4), RIF_UNUSED, RIF_UNLOCK, RIF_NSEC, RIF_PRIV, RIF_CID1, RIF_SEM_DIS, RIF_CFEN) /* Feature = EXTI1[4] */
		RIFPROT(RIF_EXTI1_RESOURCE(5), RIF_UNUSED, RIF_UNLOCK, RIF_NSEC, RIF_NPRIV, RIF_UNUSED, RIF_SEM_DIS, RIF_CFDIS) /* Feature = EXTI1[5] */
		RIFPROT(RIF_EXTI1_RESOURCE(6), RIF_UNUSED, RIF_UNLOCK, RIF_NSEC, RIF_NPRIV, RIF_UNUSED, RIF_SEM_DIS, RIF_CFDIS) /* Feature = EXTI1[6] */
		RIFPROT(RIF_EXTI1_RESOURCE(7), RIF_UNUSED, RIF_UNLOCK, RIF_NSEC, RIF_NPRIV, RIF_UNUSED, RIF_SEM_DIS, RIF_CFDIS) /* Feature = EXTI1[7] */
		RIFPROT(RIF_EXTI1_RESOURCE(8), RIF_UNUSED, RIF_UNLOCK, RIF_NSEC, RIF_NPRIV, RIF_CID2, RIF_SEM_DIS, RIF_CFEN) /* Feature = EXTI1[8] */
		RIFPROT(RIF_EXTI1_RESOURCE(9), RIF_UNUSED, RIF_UNLOCK, RIF_NSEC, RIF_NPRIV, RIF_UNUSED, RIF_SEM_DIS, RIF_CFDIS) /* Feature = EXTI1[9] */
		RIFPROT(RIF_EXTI1_RESOURCE(10), RIF_UNUSED, RIF_UNLOCK, RIF_NSEC, RIF_NPRIV, RIF_UNUSED, RIF_SEM_DIS, RIF_CFDIS) /* Feature = EXTI1[10] */
		RIFPROT(RIF_EXTI1_RESOURCE(11), RIF_UNUSED, RIF_UNLOCK, RIF_NSEC, RIF_NPRIV, RIF_UNUSED, RIF_SEM_DIS, RIF_CFDIS) /* Feature = EXTI1[11] */
		RIFPROT(RIF_EXTI1_RESOURCE(12), RIF_UNUSED, RIF_UNLOCK, RIF_NSEC, RIF_NPRIV, RIF_UNUSED, RIF_SEM_DIS, RIF_CFDIS) /* Feature = EXTI1[12] */
		RIFPROT(RIF_EXTI1_RESOURCE(13), RIF_UNUSED, RIF_UNLOCK, RIF_NSEC, RIF_PRIV, RIF_CID1, RIF_SEM_DIS, RIF_CFEN) /* Feature = EXTI1[13] */
		RIFPROT(RIF_EXTI1_RESOURCE(14), RIF_UNUSED, RIF_UNLOCK, RIF_NSEC, RIF_NPRIV, RIF_UNUSED, RIF_SEM_DIS, RIF_CFDIS) /* Feature = EXTI1[14] */
		RIFPROT(RIF_EXTI1_RESOURCE(15), RIF_UNUSED, RIF_UNLOCK, RIF_NSEC, RIF_NPRIV, RIF_UNUSED, RIF_SEM_DIS, RIF_CFDIS) /* Feature = EXTI1[15] */
		RIFPROT(RIF_EXTI1_RESOURCE(16), RIF_UNUSED, RIF_UNLOCK, RIF_SEC, RIF_PRIV, RIF_CID1, RIF_SEM_DIS, RIF_CFEN) /* Feature = PVD */
		RIFPROT(RIF_EXTI1_RESOURCE(17), RIF_UNUSED, RIF_UNLOCK, RIF_SEC, RIF_PRIV, RIF_CID1, RIF_SEM_DIS, RIF_CFEN) /* Feature = PVM */
		RIFPROT(RIF_EXTI1_RESOURCE(18), RIF_UNUSED, RIF_UNLOCK, RIF_NSEC, RIF_NPRIV, RIF_UNUSED, RIF_SEM_DIS, RIF_CFDIS) /* Feature = VDDGPU_VD */
		RIFPROT(RIF_EXTI1_RESOURCE(19), RIF_UNUSED, RIF_UNLOCK, RIF_SEC, RIF_PRIV, RIF_CID1, RIF_SEM_DIS, RIF_CFEN) /* Feature = RCC_HSI_FMON */
		RIFPROT(RIF_EXTI1_RESOURCE(21), RIF_UNUSED, RIF_UNLOCK, RIF_NSEC, RIF_NPRIV, RIF_CID2, RIF_SEM_DIS, RIF_CFEN) /* Feature = I2C1 */
		RIFPROT(RIF_EXTI1_RESOURCE(22), RIF_UNUSED, RIF_UNLOCK, RIF_NSEC, RIF_NPRIV, RIF_CID1, RIF_SEM_DIS, RIF_CFEN) /* Feature = I2C2 */
		RIFPROT(RIF_EXTI1_RESOURCE(23), RIF_UNUSED, RIF_UNLOCK, RIF_NSEC, RIF_NPRIV, RIF_UNUSED, RIF_SEM_DIS, RIF_CFDIS) /* Feature = I2C3 */
		RIFPROT(RIF_EXTI1_RESOURCE(24), RIF_UNUSED, RIF_UNLOCK, RIF_NSEC, RIF_NPRIV, RIF_UNUSED, RIF_SEM_DIS, RIF_CFDIS) /* Feature = I2C4 */
		RIFPROT(RIF_EXTI1_RESOURCE(25), RIF_UNUSED, RIF_UNLOCK, RIF_NSEC, RIF_NPRIV, RIF_UNUSED, RIF_SEM_DIS, RIF_CFDIS) /* Feature = I2C5 */
		RIFPROT(RIF_EXTI1_RESOURCE(26), RIF_UNUSED, RIF_UNLOCK, RIF_NSEC, RIF_NPRIV, RIF_UNUSED, RIF_SEM_DIS, RIF_CFDIS) /* Feature = USART1 */
		RIFPROT(RIF_EXTI1_RESOURCE(27), RIF_UNUSED, RIF_UNLOCK, RIF_NSEC, RIF_PRIV, RIF_CID1, RIF_SEM_DIS, RIF_CFEN) /* Feature = USART2 */
		RIFPROT(RIF_EXTI1_RESOURCE(28), RIF_UNUSED, RIF_UNLOCK, RIF_NSEC, RIF_NPRIV, RIF_UNUSED, RIF_SEM_DIS, RIF_CFDIS) /* Feature = USART3 */
		RIFPROT(RIF_EXTI1_RESOURCE(29), RIF_UNUSED, RIF_UNLOCK, RIF_SEC, RIF_NPRIV, RIF_CID2, RIF_SEM_DIS, RIF_CFEN) /* Feature = USART6 */
		RIFPROT(RIF_EXTI1_RESOURCE(30), RIF_UNUSED, RIF_UNLOCK, RIF_NSEC, RIF_NPRIV, RIF_UNUSED, RIF_SEM_DIS, RIF_CFDIS) /* Feature = UART4 */
		RIFPROT(RIF_EXTI1_RESOURCE(31), RIF_UNUSED, RIF_UNLOCK, RIF_SEC, RIF_NPRIV, RIF_CID2, RIF_SEM_DIS, RIF_CFEN) /* Feature = UART5 */
		RIFPROT(RIF_EXTI1_RESOURCE(32), RIF_UNUSED, RIF_UNLOCK, RIF_NSEC, RIF_NPRIV, RIF_UNUSED, RIF_SEM_DIS, RIF_CFDIS) /* Feature = UART7 */
		RIFPROT(RIF_EXTI1_RESOURCE(33), RIF_UNUSED, RIF_UNLOCK, RIF_NSEC, RIF_NPRIV, RIF_UNUSED, RIF_SEM_DIS, RIF_CFDIS) /* Feature = UART8 */
		RIFPROT(RIF_EXTI1_RESOURCE(34), RIF_UNUSED, RIF_UNLOCK, RIF_NSEC, RIF_NPRIV, RIF_UNUSED, RIF_SEM_DIS, RIF_CFDIS) /* Feature = UART9 */
		RIFPROT(RIF_EXTI1_RESOURCE(36), RIF_UNUSED, RIF_UNLOCK, RIF_NSEC, RIF_NPRIV, RIF_UNUSED, RIF_SEM_DIS, RIF_CFDIS) /* Feature = SPI1 */
		RIFPROT(RIF_EXTI1_RESOURCE(37), RIF_UNUSED, RIF_UNLOCK, RIF_NSEC, RIF_NPRIV, RIF_UNUSED, RIF_SEM_DIS, RIF_CFDIS) /* Feature = SPI2 */
		RIFPROT(RIF_EXTI1_RESOURCE(38), RIF_UNUSED, RIF_UNLOCK, RIF_NSEC, RIF_NPRIV, RIF_UNUSED, RIF_SEM_DIS, RIF_CFDIS) /* Feature = SPI3 */
		RIFPROT(RIF_EXTI1_RESOURCE(39), RIF_UNUSED, RIF_UNLOCK, RIF_NSEC, RIF_NPRIV, RIF_UNUSED, RIF_SEM_DIS, RIF_CFDIS) /* Feature = SPI4 */
		RIFPROT(RIF_EXTI1_RESOURCE(40), RIF_UNUSED, RIF_UNLOCK, RIF_NSEC, RIF_NPRIV, RIF_UNUSED, RIF_SEM_DIS, RIF_CFDIS) /* Feature = SPI5 */
		RIFPROT(RIF_EXTI1_RESOURCE(41), RIF_UNUSED, RIF_UNLOCK, RIF_NSEC, RIF_NPRIV, RIF_UNUSED, RIF_SEM_DIS, RIF_CFDIS) /* Feature = SPI6 */
		RIFPROT(RIF_EXTI1_RESOURCE(42), RIF_UNUSED, RIF_UNLOCK, RIF_NSEC, RIF_NPRIV, RIF_UNUSED, RIF_SEM_DIS, RIF_CFDIS) /* Feature = SPI7 */
		RIFPROT(RIF_EXTI1_RESOURCE(43), RIF_UNUSED, RIF_UNLOCK, RIF_NSEC, RIF_PRIV, RIF_CID1, RIF_SEM_DIS, RIF_CFEN) /* Feature = USBH */
		RIFPROT(RIF_EXTI1_RESOURCE(44), RIF_UNUSED, RIF_UNLOCK, RIF_NSEC, RIF_PRIV, RIF_CID1, RIF_SEM_DIS, RIF_CFEN) /* Feature = USB3DR */
		RIFPROT(RIF_EXTI1_RESOURCE(45), RIF_UNUSED, RIF_UNLOCK, RIF_NSEC, RIF_PRIV, RIF_CID1, RIF_SEM_DIS, RIF_CFEN) /* Feature = COMBOPHY */
		RIFPROT(RIF_EXTI1_RESOURCE(46), RIF_UNUSED, RIF_UNLOCK, RIF_NSEC, RIF_NPRIV, RIF_CID2, RIF_SEM_DIS, RIF_CFEN) /* Feature = UCPD */
		RIFPROT(RIF_EXTI1_RESOURCE(47), RIF_UNUSED, RIF_UNLOCK, RIF_SEC, RIF_PRIV, RIF_CID1, RIF_SEM_DIS, RIF_CFEN) /* Feature = LPTIM1 */
		RIFPROT(RIF_EXTI1_RESOURCE(48), RIF_UNUSED, RIF_UNLOCK, RIF_NSEC, RIF_PRIV, RIF_UNUSED, RIF_SEM_DIS, RIF_CFDIS) /* Feature = LPTIM2 */
		RIFPROT(RIF_EXTI1_RESOURCE(49), RIF_UNUSED, RIF_UNLOCK, RIF_NSEC, RIF_NPRIV, RIF_UNUSED, RIF_SEM_DIS, RIF_CFDIS) /* Feature = I2C6 */
		RIFPROT(RIF_EXTI1_RESOURCE(50), RIF_UNUSED, RIF_UNLOCK, RIF_SEC, RIF_PRIV, RIF_CID1, RIF_SEM_DIS, RIF_CFEN) /* Feature = I2C7 */
		RIFPROT(RIF_EXTI1_RESOURCE(52), RIF_UNUSED, RIF_UNLOCK, RIF_NSEC, RIF_PRIV, RIF_CID1, RIF_SEM_DIS, RIF_CFEN) /* Feature = WKUP1 wakeup */
		RIFPROT(RIF_EXTI1_RESOURCE(53), RIF_UNUSED, RIF_UNLOCK, RIF_NSEC, RIF_PRIV, RIF_CID1, RIF_SEM_DIS, RIF_CFEN) /* Feature = WKUP2 wakeup */
		RIFPROT(RIF_EXTI1_RESOURCE(54), RIF_UNUSED, RIF_UNLOCK, RIF_NSEC, RIF_NPRIV, RIF_CID2, RIF_SEM_DIS, RIF_CFEN) /* Feature = WKUP3 wakeup */
		RIFPROT(RIF_EXTI1_RESOURCE(55), RIF_UNUSED, RIF_UNLOCK, RIF_NSEC, RIF_NPRIV, RIF_UNUSED, RIF_SEM_DIS, RIF_CFDIS) /* Feature = WKUP4 wakeup */
		RIFPROT(RIF_EXTI1_RESOURCE(56), RIF_UNUSED, RIF_UNLOCK, RIF_NSEC, RIF_NPRIV, RIF_UNUSED, RIF_SEM_DIS, RIF_CFDIS) /* Feature = WKUP5 wakeup */
		RIFPROT(RIF_EXTI1_RESOURCE(57), RIF_UNUSED, RIF_UNLOCK, RIF_NSEC, RIF_NPRIV, RIF_UNUSED, RIF_SEM_DIS, RIF_CFDIS) /* Feature = WKUP6 wakeup */
		RIFPROT(RIF_EXTI1_RESOURCE(59), RIF_UNUSED, RIF_UNLOCK, RIF_NSEC, RIF_PRIV, RIF_UNUSED, RIF_SEM_DIS, RIF_CFDIS) /* Feature = IPCC1 non secure interrupt CPU1 */
		RIFPROT(RIF_EXTI1_RESOURCE(60), RIF_UNUSED, RIF_UNLOCK, RIF_NSEC, RIF_NPRIV, RIF_UNUSED, RIF_SEM_DIS, RIF_CFDIS) /* Feature = IPCC1 non secure interrupt CPU2 */
		RIFPROT(RIF_EXTI1_RESOURCE(61), RIF_UNUSED, RIF_UNLOCK, RIF_NSEC, RIF_PRIV, RIF_UNUSED, RIF_SEM_DIS, RIF_CFDIS) /* Feature = IPCC1 secure interrupt CPU1 */
		RIFPROT(RIF_EXTI1_RESOURCE(62), RIF_UNUSED, RIF_UNLOCK, RIF_NSEC, RIF_PRIV, RIF_UNUSED, RIF_SEM_DIS, RIF_CFDIS) /* Feature = IPCC1 secure interrupt CPU2 */
		RIFPROT(RIF_EXTI1_RESOURCE(64), RIF_UNUSED, RIF_UNLOCK, RIF_NSEC, RIF_NPRIV, RIF_UNUSED, RIF_SEM_DIS, RIF_CFDIS) /* Feature = CPU2 SEV interrupt */
		RIFPROT(RIF_EXTI1_RESOURCE(65), RIF_UNUSED, RIF_UNLOCK, RIF_NSEC, RIF_NPRIV, RIF_UNUSED, RIF_SEM_DIS, RIF_CFDIS) /* Feature = CPU1 SEV interrupt */
		RIFPROT(RIF_EXTI1_RESOURCE(67), RIF_UNUSED, RIF_UNLOCK, RIF_NSEC, RIF_NPRIV, RIF_UNUSED, RIF_SEM_DIS, RIF_CFDIS) /* Feature = WWDG1 Reset */
		RIFPROT(RIF_EXTI1_RESOURCE(68), RIF_UNUSED, RIF_UNLOCK, RIF_NSEC, RIF_PRIV, RIF_CID1, RIF_SEM_DIS, RIF_CFEN) /* Feature = ETH1_PMT wakeup */
		RIFPROT(RIF_EXTI1_RESOURCE(69), RIF_UNUSED, RIF_UNLOCK, RIF_NSEC, RIF_PRIV, RIF_CID1, RIF_SEM_DIS, RIF_CFEN) /* Feature = ETH1_SBD */
		RIFPROT(RIF_EXTI1_RESOURCE(70), RIF_UNUSED, RIF_UNLOCK, RIF_NSEC, RIF_PRIV, RIF_CID1, RIF_SEM_DIS, RIF_CFEN) /* Feature = ETH2_PMT wakeup */
		RIFPROT(RIF_EXTI1_RESOURCE(71), RIF_UNUSED, RIF_UNLOCK, RIF_NSEC, RIF_PRIV, RIF_CID1, RIF_SEM_DIS, RIF_CFEN) /* Feature = ETH2_SBD */
		RIFPROT(RIF_EXTI1_RESOURCE(72), RIF_UNUSED, RIF_UNLOCK, RIF_NSEC, RIF_PRIV, RIF_UNUSED, RIF_SEM_DIS, RIF_CFDIS) /* Feature = DTS */
		RIFPROT(RIF_EXTI1_RESOURCE(73), RIF_UNUSED, RIF_UNLOCK, RIF_NSEC, RIF_PRIV, RIF_UNUSED, RIF_SEM_DIS, RIF_CFDIS) /* Feature = CPU2 SYSRESETREQ local CPU2 reset */
		RIFPROT(RIF_EXTI1_RESOURCE(74), RIF_UNUSED, RIF_UNLOCK, RIF_NSEC, RIF_NPRIV, RIF_UNUSED, RIF_SEM_DIS, RIF_CFDIS) /* Feature = I3C1 */
		RIFPROT(RIF_EXTI1_RESOURCE(75), RIF_UNUSED, RIF_UNLOCK, RIF_NSEC, RIF_NPRIV, RIF_UNUSED, RIF_SEM_DIS, RIF_CFDIS) /* Feature = I3C2 */
		RIFPROT(RIF_EXTI1_RESOURCE(76), RIF_UNUSED, RIF_UNLOCK, RIF_NSEC, RIF_NPRIV, RIF_UNUSED, RIF_SEM_DIS, RIF_CFDIS) /* Feature = I3C3 */
		RIFPROT(RIF_EXTI1_RESOURCE(77), RIF_UNUSED, RIF_UNLOCK, RIF_NSEC, RIF_PRIV, RIF_CID1, RIF_SEM_DIS, RIF_CFEN) /* Feature = HPDMA1 Channel 0 to 15 CPU1 irq */
		RIFPROT(RIF_EXTI1_RESOURCE(78), RIF_UNUSED, RIF_UNLOCK, RIF_NSEC, RIF_PRIV, RIF_CID1, RIF_SEM_DIS, RIF_CFEN) /* Feature = HPDMA2 Channel 0 to 15 CPU1 irq */
		RIFPROT(RIF_EXTI1_RESOURCE(79), RIF_UNUSED, RIF_UNLOCK, RIF_NSEC, RIF_PRIV, RIF_CID1, RIF_SEM_DIS, RIF_CFEN) /* Feature = HPDMA3 Channel 0 to 15 CPU1 irq */
		RIFPROT(RIF_EXTI1_RESOURCE(80), RIF_UNUSED, RIF_UNLOCK, RIF_NSEC, RIF_NPRIV, RIF_CID2, RIF_SEM_DIS, RIF_CFEN) /* Feature = HPDMA1 Channel 0 to 15 CPU2 irq */
		RIFPROT(RIF_EXTI1_RESOURCE(81), RIF_UNUSED, RIF_UNLOCK, RIF_NSEC, RIF_NPRIV, RIF_CID2, RIF_SEM_DIS, RIF_CFEN) /* Feature = HPDMA2 Channel 0 to 15 CPU2 irq */
		RIFPROT(RIF_EXTI1_RESOURCE(82), RIF_UNUSED, RIF_UNLOCK, RIF_NSEC, RIF_NPRIV, RIF_CID2, RIF_SEM_DIS, RIF_CFEN) /* Feature = HPDMA3 Channel 0 to 15 CPU2 irq */
		RIFPROT(RIF_EXTI1_RESOURCE(83), RIF_UNUSED, RIF_UNLOCK, RIF_NSEC, RIF_NPRIV, RIF_CID2, RIF_SEM_DIS, RIF_CFEN) /* Feature = UCPD VBUS DETECT */
		RIFPROT(RIF_EXTI1_RESOURCE(84), RIF_UNUSED, RIF_UNLOCK, RIF_NSEC, RIF_NPRIV, RIF_CID2, RIF_SEM_DIS, RIF_CFEN) /* Feature = UCPD VBUS VSAFE5V */
	>;
	st,proccid = <1 RIF_CID1>, <2 RIF_CID2>;
};

&fmc{

	st,protreg = <
		RIFPROT(RIF_FMC_CTRL(0), EMPTY_SEMWL, RIF_UNLOCK, RIF_NSEC, RIF_NPRIV, RIF_UNUSED, RIF_SEM_EN, RIF_CFEN) /* Feature = FMC_CFGR */
		RIFPROT(RIF_FMC_CTRL(1), EMPTY_SEMWL, RIF_UNLOCK, RIF_NSEC, RIF_NPRIV, RIF_UNUSED, RIF_SEM_EN, RIF_CFEN) /* Feature = FMC_NOR/PSRAM1 */
		RIFPROT(RIF_FMC_CTRL(2), EMPTY_SEMWL, RIF_UNLOCK, RIF_NSEC, RIF_NPRIV, RIF_UNUSED, RIF_SEM_EN, RIF_CFEN) /* Feature = FMC_NOR/PSRAM2 */
		RIFPROT(RIF_FMC_CTRL(3), EMPTY_SEMWL, RIF_UNLOCK, RIF_NSEC, RIF_NPRIV, RIF_UNUSED, RIF_SEM_EN, RIF_CFEN) /* Feature = FMC_NOR/PSRAM3 */
		RIFPROT(RIF_FMC_CTRL(4), EMPTY_SEMWL, RIF_UNLOCK, RIF_NSEC, RIF_NPRIV, RIF_UNUSED, RIF_SEM_EN, RIF_CFEN) /* Feature = FMC_NOR/PSRAM4 */
		RIFPROT(RIF_FMC_CTRL(5), EMPTY_SEMWL, RIF_UNLOCK, RIF_NSEC, RIF_NPRIV, RIF_UNUSED, RIF_SEM_EN, RIF_CFEN) /* Feature = FMC_NAND */
	>;
};

&gpioa{

	st,protreg = <
		RIFPROT(RIF_IOPORT_PIN(0), RIF_UNUSED,  RIF_UNLOCK, RIF_SEC, RIF_PRIV, RIF_CID1, RIF_SEM_DIS, RIF_CFEN) /* PA0 */
		RIFPROT(RIF_IOPORT_PIN(1), RIF_UNUSED,  RIF_UNLOCK, RIF_NSEC, RIF_PRIV, RIF_CID1, RIF_SEM_DIS, RIF_CFEN) /* PA1 */
		RIFPROT(RIF_IOPORT_PIN(2), RIF_UNUSED,  RIF_UNLOCK, RIF_NSEC, RIF_PRIV, RIF_CID1, RIF_SEM_DIS, RIF_CFEN) /* PA2 */
		RIFPROT(RIF_IOPORT_PIN(3), RIF_UNUSED,  RIF_UNLOCK, RIF_NSEC, RIF_PRIV, RIF_CID1, RIF_SEM_DIS, RIF_CFEN) /* PA3 */
		RIFPROT(RIF_IOPORT_PIN(4), RIF_UNUSED,  RIF_UNLOCK, RIF_NSEC, RIF_PRIV, RIF_CID1, RIF_SEM_DIS, RIF_CFEN) /* PA4 */
		RIFPROT(RIF_IOPORT_PIN(5), RIF_UNUSED,  RIF_UNLOCK, RIF_NSEC, RIF_PRIV, RIF_CID1, RIF_SEM_DIS, RIF_CFEN) /* PA5 */
		RIFPROT(RIF_IOPORT_PIN(6), RIF_UNUSED,  RIF_UNLOCK, RIF_NSEC, RIF_PRIV, RIF_CID1, RIF_SEM_DIS, RIF_CFEN) /* PA6 */
		RIFPROT(RIF_IOPORT_PIN(7), RIF_UNUSED,  RIF_UNLOCK, RIF_NSEC, RIF_PRIV, RIF_CID1, RIF_SEM_DIS, RIF_CFEN) /* PA7 */
		RIFPROT(RIF_IOPORT_PIN(8), RIF_UNUSED,  RIF_UNLOCK, RIF_NSEC, RIF_PRIV, RIF_CID1, RIF_SEM_DIS, RIF_CFEN) /* PA8 */
		RIFPROT(RIF_IOPORT_PIN(9), RIF_UNUSED,  RIF_UNLOCK, RIF_NSEC, RIF_PRIV, RIF_CID1, RIF_SEM_DIS, RIF_CFEN) /* PA9 */
		RIFPROT(RIF_IOPORT_PIN(10), RIF_UNUSED,  RIF_UNLOCK, RIF_NSEC, RIF_PRIV, RIF_CID1, RIF_SEM_DIS, RIF_CFEN) /* PA10 */
		RIFPROT(RIF_IOPORT_PIN(11), RIF_UNUSED,  RIF_UNLOCK, RIF_NSEC, RIF_PRIV, RIF_CID1, RIF_SEM_DIS, RIF_CFEN) /* PA11 */
		RIFPROT(RIF_IOPORT_PIN(12), RIF_UNUSED,  RIF_UNLOCK, RIF_NSEC, RIF_PRIV, RIF_CID1, RIF_SEM_DIS, RIF_CFEN) /* PA12 */
		RIFPROT(RIF_IOPORT_PIN(13), RIF_UNUSED,  RIF_UNLOCK, RIF_NSEC, RIF_PRIV, RIF_CID1, RIF_SEM_DIS, RIF_CFEN) /* PA13 */
		RIFPROT(RIF_IOPORT_PIN(14), RIF_UNUSED,  RIF_UNLOCK, RIF_NSEC, RIF_PRIV, RIF_CID1, RIF_SEM_DIS, RIF_CFEN) /* PA14 */
		RIFPROT(RIF_IOPORT_PIN(15), RIF_UNUSED,  RIF_UNLOCK, RIF_NSEC, RIF_PRIV, RIF_CID1, RIF_SEM_DIS, RIF_CFEN) /* PA15 */
	>;
};

&gpiob{

	st,protreg = <
		RIFPROT(RIF_IOPORT_PIN(0), EMPTY_SEMWL,  RIF_UNLOCK, RIF_NSEC, RIF_PRIV, RIF_UNUSED, RIF_SEM_EN, RIF_CFEN) /* PB0 */
		RIFPROT(RIF_IOPORT_PIN(1), RIF_UNUSED,  RIF_UNLOCK, RIF_NSEC, RIF_PRIV, RIF_CID1, RIF_SEM_DIS, RIF_CFEN) /* PB1 */
		RIFPROT(RIF_IOPORT_PIN(2), EMPTY_SEMWL,  RIF_UNLOCK, RIF_NSEC, RIF_NPRIV, RIF_UNUSED, RIF_SEM_EN, RIF_CFEN) /* PB2 */
		RIFPROT(RIF_IOPORT_PIN(3), RIF_UNUSED,  RIF_UNLOCK, RIF_NSEC, RIF_PRIV, RIF_CID1, RIF_SEM_DIS, RIF_CFEN) /* PB3 */
		RIFPROT(RIF_IOPORT_PIN(4), RIF_UNUSED,  RIF_UNLOCK, RIF_NSEC, RIF_PRIV, RIF_CID1, RIF_SEM_DIS, RIF_CFEN) /* PB4 */
		RIFPROT(RIF_IOPORT_PIN(5), RIF_UNUSED,  RIF_UNLOCK, RIF_NSEC, RIF_PRIV, RIF_CID1, RIF_SEM_DIS, RIF_CFEN) /* PB5 */
		RIFPROT(RIF_IOPORT_PIN(6), EMPTY_SEMWL,  RIF_UNLOCK, RIF_NSEC, RIF_NPRIV, RIF_UNUSED, RIF_SEM_EN, RIF_CFEN) /* PB6 */
		RIFPROT(RIF_IOPORT_PIN(7), RIF_UNUSED,  RIF_UNLOCK, RIF_NSEC, RIF_PRIV, RIF_CID1, RIF_SEM_DIS, RIF_CFEN) /* PB7 */
		RIFPROT(RIF_IOPORT_PIN(8), EMPTY_SEMWL,  RIF_UNLOCK, RIF_NSEC, RIF_PRIV, RIF_UNUSED, RIF_SEM_EN, RIF_CFEN) /* PB8 */
		RIFPROT(RIF_IOPORT_PIN(9), EMPTY_SEMWL,  RIF_UNLOCK, RIF_NSEC, RIF_PRIV, RIF_UNUSED, RIF_SEM_EN, RIF_CFEN) /* PB9 */
		RIFPROT(RIF_IOPORT_PIN(10), RIF_UNUSED,  RIF_UNLOCK, RIF_NSEC, RIF_PRIV, RIF_CID1, RIF_SEM_DIS, RIF_CFEN) /* PB10 */
		RIFPROT(RIF_IOPORT_PIN(11), EMPTY_SEMWL,  RIF_UNLOCK, RIF_NSEC, RIF_PRIV, RIF_UNUSED, RIF_SEM_EN, RIF_CFEN) /* PB11 */
		RIFPROT(RIF_IOPORT_PIN(12), RIF_UNUSED,  RIF_UNLOCK, RIF_NSEC, RIF_PRIV, RIF_CID1, RIF_SEM_DIS, RIF_CFEN) /* PB12 */
		RIFPROT(RIF_IOPORT_PIN(13), RIF_UNUSED,  RIF_UNLOCK, RIF_NSEC, RIF_PRIV, RIF_CID1, RIF_SEM_DIS, RIF_CFEN) /* PB13 */
		RIFPROT(RIF_IOPORT_PIN(14), RIF_UNUSED,  RIF_UNLOCK, RIF_NSEC, RIF_PRIV, RIF_CID1, RIF_SEM_DIS, RIF_CFEN) /* PB14 */
		RIFPROT(RIF_IOPORT_PIN(15), RIF_UNUSED,  RIF_UNLOCK, RIF_NSEC, RIF_PRIV, RIF_CID1, RIF_SEM_DIS, RIF_CFEN) /* PB15 */
	>;
};

&gpioc{

	st,protreg = <
		RIFPROT(RIF_IOPORT_PIN(0), RIF_UNUSED,  RIF_UNLOCK, RIF_NSEC, RIF_PRIV, RIF_CID1, RIF_SEM_DIS, RIF_CFEN) /* PC0 */
		RIFPROT(RIF_IOPORT_PIN(1), RIF_UNUSED,  RIF_UNLOCK, RIF_NSEC, RIF_PRIV, RIF_CID1, RIF_SEM_DIS, RIF_CFEN) /* PC1 */
		RIFPROT(RIF_IOPORT_PIN(2), RIF_UNUSED,  RIF_UNLOCK, RIF_NSEC, RIF_PRIV, RIF_CID1, RIF_SEM_DIS, RIF_CFEN) /* PC2 */
		RIFPROT(RIF_IOPORT_PIN(3), RIF_UNUSED,  RIF_UNLOCK, RIF_NSEC, RIF_PRIV, RIF_CID1, RIF_SEM_DIS, RIF_CFEN) /* PC3 */
		RIFPROT(RIF_IOPORT_PIN(4), RIF_UNUSED,  RIF_UNLOCK, RIF_NSEC, RIF_PRIV, RIF_CID1, RIF_SEM_DIS, RIF_CFEN) /* PC4 */
		RIFPROT(RIF_IOPORT_PIN(5), RIF_UNUSED,  RIF_UNLOCK, RIF_NSEC, RIF_PRIV, RIF_CID1, RIF_SEM_DIS, RIF_CFEN) /* PC5 */
		RIFPROT(RIF_IOPORT_PIN(6), RIF_UNUSED,  RIF_UNLOCK, RIF_NSEC, RIF_PRIV, RIF_CID1, RIF_SEM_DIS, RIF_CFEN) /* PC6 */
		RIFPROT(RIF_IOPORT_PIN(7), RIF_UNUSED,  RIF_UNLOCK, RIF_NSEC, RIF_PRIV, RIF_CID1, RIF_SEM_DIS, RIF_CFEN) /* PC7 */
		RIFPROT(RIF_IOPORT_PIN(8), RIF_UNUSED,  RIF_UNLOCK, RIF_NSEC, RIF_PRIV, RIF_CID1, RIF_SEM_DIS, RIF_CFEN) /* PC8 */
		RIFPROT(RIF_IOPORT_PIN(9), RIF_UNUSED,  RIF_UNLOCK, RIF_NSEC, RIF_PRIV, RIF_CID1, RIF_SEM_DIS, RIF_CFEN) /* PC9 */
		RIFPROT(RIF_IOPORT_PIN(10), RIF_UNUSED,  RIF_UNLOCK, RIF_NSEC, RIF_PRIV, RIF_CID1, RIF_SEM_DIS, RIF_CFEN) /* PC10 */
		RIFPROT(RIF_IOPORT_PIN(11), RIF_UNUSED,  RIF_UNLOCK, RIF_NSEC, RIF_PRIV, RIF_CID1, RIF_SEM_DIS, RIF_CFEN) /* PC11 */
		RIFPROT(RIF_IOPORT_PIN(12), RIF_UNUSED,  RIF_UNLOCK, RIF_NSEC, RIF_PRIV, RIF_CID1, RIF_SEM_DIS, RIF_CFEN) /* PC12 */
		RIFPROT(RIF_IOPORT_PIN(13), EMPTY_SEMWL,  RIF_UNLOCK, RIF_NSEC, RIF_NPRIV, RIF_UNUSED, RIF_SEM_EN, RIF_CFEN) /* PC13 */
	>;
};

&gpiod{

	st,protreg = <
		RIFPROT(RIF_IOPORT_PIN(0), RIF_UNUSED,  RIF_UNLOCK, RIF_SEC, RIF_PRIV, RIF_CID1, RIF_SEM_DIS, RIF_CFEN) /* PD0 */
		RIFPROT(RIF_IOPORT_PIN(1), EMPTY_SEMWL,  RIF_UNLOCK, RIF_NSEC, RIF_PRIV, RIF_UNUSED, RIF_SEM_EN, RIF_CFEN) /* PD1 */
		RIFPROT(RIF_IOPORT_PIN(2), EMPTY_SEMWL,  RIF_UNLOCK, RIF_NSEC, RIF_NPRIV, RIF_UNUSED, RIF_SEM_EN, RIF_CFEN) /* PD2 */
		RIFPROT(RIF_IOPORT_PIN(3), RIF_UNUSED,  RIF_UNLOCK, RIF_SEC, RIF_PRIV, RIF_CID1, RIF_SEM_DIS, RIF_CFEN) /* PD3 */
		RIFPROT(RIF_IOPORT_PIN(4), RIF_UNUSED,  RIF_UNLOCK, RIF_SEC, RIF_PRIV, RIF_CID1, RIF_SEM_DIS, RIF_CFEN) /* PD4 */
		RIFPROT(RIF_IOPORT_PIN(5), RIF_UNUSED,  RIF_UNLOCK, RIF_SEC, RIF_PRIV, RIF_CID1, RIF_SEM_DIS, RIF_CFEN) /* PD5 */
		RIFPROT(RIF_IOPORT_PIN(6), RIF_UNUSED,  RIF_UNLOCK, RIF_SEC, RIF_PRIV, RIF_CID1, RIF_SEM_DIS, RIF_CFEN) /* PD6 */
		RIFPROT(RIF_IOPORT_PIN(7), RIF_UNUSED,  RIF_UNLOCK, RIF_SEC, RIF_PRIV, RIF_CID1, RIF_SEM_DIS, RIF_CFEN) /* PD7 */
		RIFPROT(RIF_IOPORT_PIN(8), RIF_UNUSED,  RIF_UNLOCK, RIF_NSEC, RIF_PRIV, RIF_CID1, RIF_SEM_DIS, RIF_CFEN) /* PD8 */
		RIFPROT(RIF_IOPORT_PIN(9), RIF_UNUSED,  RIF_UNLOCK, RIF_NSEC, RIF_PRIV, RIF_CID1, RIF_SEM_DIS, RIF_CFEN) /* PD9 */
		RIFPROT(RIF_IOPORT_PIN(10), RIF_UNUSED,  RIF_UNLOCK, RIF_NSEC, RIF_PRIV, RIF_CID1, RIF_SEM_DIS, RIF_CFEN) /* PD10 */
		RIFPROT(RIF_IOPORT_PIN(11), RIF_UNUSED,  RIF_UNLOCK, RIF_NSEC, RIF_PRIV, RIF_CID1, RIF_SEM_DIS, RIF_CFEN) /* PD11 */
		RIFPROT(RIF_IOPORT_PIN(12), RIF_UNUSED,  RIF_UNLOCK, RIF_NSEC, RIF_PRIV, RIF_CID1, RIF_SEM_DIS, RIF_CFEN) /* PD12 */
		RIFPROT(RIF_IOPORT_PIN(13), RIF_UNUSED,  RIF_UNLOCK, RIF_NSEC, RIF_PRIV, RIF_CID1, RIF_SEM_DIS, RIF_CFEN) /* PD13 */
		RIFPROT(RIF_IOPORT_PIN(14), RIF_UNUSED,  RIF_UNLOCK, RIF_SEC, RIF_PRIV, RIF_CID1, RIF_SEM_DIS, RIF_CFEN) /* PD14 */
		RIFPROT(RIF_IOPORT_PIN(15), RIF_UNUSED,  RIF_UNLOCK, RIF_SEC, RIF_PRIV, RIF_CID1, RIF_SEM_DIS, RIF_CFEN) /* PD15 */
	>;
};

&gpioe{

	st,protreg = <
		RIFPROT(RIF_IOPORT_PIN(0), RIF_UNUSED,  RIF_UNLOCK, RIF_NSEC, RIF_PRIV, RIF_CID1, RIF_SEM_DIS, RIF_CFEN) /* PE0 */
		RIFPROT(RIF_IOPORT_PIN(1), RIF_UNUSED,  RIF_UNLOCK, RIF_NSEC, RIF_PRIV, RIF_CID1, RIF_SEM_DIS, RIF_CFEN) /* PE1 */
		RIFPROT(RIF_IOPORT_PIN(2), RIF_UNUSED,  RIF_UNLOCK, RIF_NSEC, RIF_PRIV, RIF_CID1, RIF_SEM_DIS, RIF_CFEN) /* PE2 */
		RIFPROT(RIF_IOPORT_PIN(3), RIF_UNUSED,  RIF_UNLOCK, RIF_NSEC, RIF_PRIV, RIF_CID1, RIF_SEM_DIS, RIF_CFEN) /* PE3 */
		RIFPROT(RIF_IOPORT_PIN(4), RIF_UNUSED,  RIF_UNLOCK, RIF_NSEC, RIF_PRIV, RIF_CID1, RIF_SEM_DIS, RIF_CFEN) /* PE4 */
		RIFPROT(RIF_IOPORT_PIN(5), RIF_UNUSED,  RIF_UNLOCK, RIF_NSEC, RIF_PRIV, RIF_CID1, RIF_SEM_DIS, RIF_CFEN) /* PE5 */
		RIFPROT(RIF_IOPORT_PIN(6), RIF_UNUSED,  RIF_UNLOCK, RIF_NSEC, RIF_PRIV, RIF_CID1, RIF_SEM_DIS, RIF_CFEN) /* PE6 */
		RIFPROT(RIF_IOPORT_PIN(7), RIF_UNUSED,  RIF_UNLOCK, RIF_NSEC, RIF_PRIV, RIF_CID1, RIF_SEM_DIS, RIF_CFEN) /* PE7 */
		RIFPROT(RIF_IOPORT_PIN(8), EMPTY_SEMWL,  RIF_UNLOCK, RIF_NSEC, RIF_PRIV, RIF_UNUSED, RIF_SEM_EN, RIF_CFEN) /* PE8 */
		RIFPROT(RIF_IOPORT_PIN(9), RIF_UNUSED,  RIF_UNLOCK, RIF_NSEC, RIF_PRIV, RIF_CID1, RIF_SEM_DIS, RIF_CFEN) /* PE9 */
		RIFPROT(RIF_IOPORT_PIN(10), RIF_UNUSED,  RIF_UNLOCK, RIF_NSEC, RIF_PRIV, RIF_CID1, RIF_SEM_DIS, RIF_CFEN) /* PE10 */
		RIFPROT(RIF_IOPORT_PIN(11), EMPTY_SEMWL,  RIF_UNLOCK, RIF_NSEC, RIF_PRIV, RIF_UNUSED, RIF_SEM_EN, RIF_CFEN) /* PE11 */
		RIFPROT(RIF_IOPORT_PIN(12), EMPTY_SEMWL,  RIF_UNLOCK, RIF_NSEC, RIF_PRIV, RIF_UNUSED, RIF_SEM_EN, RIF_CFEN) /* PE12 */
		RIFPROT(RIF_IOPORT_PIN(13), EMPTY_SEMWL,  RIF_UNLOCK, RIF_NSEC, RIF_NPRIV, RIF_UNUSED, RIF_SEM_EN, RIF_CFEN) /* PE13 */
		RIFPROT(RIF_IOPORT_PIN(14), EMPTY_SEMWL,  RIF_UNLOCK, RIF_NSEC, RIF_NPRIV, RIF_UNUSED, RIF_SEM_EN, RIF_CFEN) /* PE14 */
		RIFPROT(RIF_IOPORT_PIN(15), EMPTY_SEMWL,  RIF_UNLOCK, RIF_NSEC, RIF_NPRIV, RIF_UNUSED, RIF_SEM_EN, RIF_CFEN) /* PE15 */
	>;
};

&gpiof{

	st,protreg = <
		RIFPROT(RIF_IOPORT_PIN(0), RIF_UNUSED,  RIF_UNLOCK, RIF_NSEC, RIF_PRIV, RIF_CID1, RIF_SEM_DIS, RIF_CFEN) /* PF0 */
		RIFPROT(RIF_IOPORT_PIN(1), RIF_UNUSED,  RIF_UNLOCK, RIF_NSEC, RIF_PRIV, RIF_CID1, RIF_SEM_DIS, RIF_CFEN) /* PF1 */
		RIFPROT(RIF_IOPORT_PIN(2), RIF_UNUSED,  RIF_UNLOCK, RIF_NSEC, RIF_PRIV, RIF_CID1, RIF_SEM_DIS, RIF_CFEN) /* PF2 */
		RIFPROT(RIF_IOPORT_PIN(3), RIF_UNUSED,  RIF_UNLOCK, RIF_NSEC, RIF_PRIV, RIF_CID1, RIF_SEM_DIS, RIF_CFEN) /* PF3 */
		RIFPROT(RIF_IOPORT_PIN(4), RIF_UNUSED,  RIF_UNLOCK, RIF_NSEC, RIF_PRIV, RIF_CID1, RIF_SEM_DIS, RIF_CFEN) /* PF4 */
		RIFPROT(RIF_IOPORT_PIN(5), RIF_UNUSED,  RIF_UNLOCK, RIF_NSEC, RIF_PRIV, RIF_CID1, RIF_SEM_DIS, RIF_CFEN) /* PF5 */
		RIFPROT(RIF_IOPORT_PIN(6), RIF_UNUSED,  RIF_UNLOCK, RIF_NSEC, RIF_PRIV, RIF_CID1, RIF_SEM_DIS, RIF_CFEN) /* PF6 */
		RIFPROT(RIF_IOPORT_PIN(7), RIF_UNUSED,  RIF_UNLOCK, RIF_NSEC, RIF_PRIV, RIF_CID1, RIF_SEM_DIS, RIF_CFEN) /* PF7 */
		RIFPROT(RIF_IOPORT_PIN(8), RIF_UNUSED,  RIF_UNLOCK, RIF_NSEC, RIF_PRIV, RIF_CID1, RIF_SEM_DIS, RIF_CFEN) /* PF8 */
		RIFPROT(RIF_IOPORT_PIN(9), RIF_UNUSED,  RIF_UNLOCK, RIF_NSEC, RIF_PRIV, RIF_CID1, RIF_SEM_DIS, RIF_CFEN) /* PF9 */
		RIFPROT(RIF_IOPORT_PIN(10), RIF_UNUSED,  RIF_UNLOCK, RIF_NSEC, RIF_PRIV, RIF_CID2, RIF_SEM_DIS, RIF_CFEN) /* PF10 */
		RIFPROT(RIF_IOPORT_PIN(11), RIF_UNUSED,  RIF_UNLOCK, RIF_NSEC, RIF_PRIV, RIF_CID2, RIF_SEM_DIS, RIF_CFEN) /* PF11 */
		RIFPROT(RIF_IOPORT_PIN(12), EMPTY_SEMWL,  RIF_UNLOCK, RIF_NSEC, RIF_PRIV, RIF_UNUSED, RIF_SEM_EN, RIF_CFEN) /* PF12 */
		RIFPROT(RIF_IOPORT_PIN(13), RIF_UNUSED,  RIF_UNLOCK, RIF_SEC, RIF_PRIV, RIF_CID2, RIF_SEM_DIS, RIF_CFEN) /* PF13 */
		RIFPROT(RIF_IOPORT_PIN(14), RIF_UNUSED,  RIF_UNLOCK, RIF_SEC, RIF_PRIV, RIF_CID2, RIF_SEM_DIS, RIF_CFEN) /* PF14 */
		RIFPROT(RIF_IOPORT_PIN(15), RIF_UNUSED,  RIF_UNLOCK, RIF_NSEC, RIF_PRIV, RIF_CID2, RIF_SEM_DIS, RIF_CFEN) /* PF15 */
	>;
};

&gpiog{

	st,protreg = <
		RIFPROT(RIF_IOPORT_PIN(0), RIF_UNUSED,  RIF_UNLOCK, RIF_NSEC, RIF_PRIV, RIF_CID1, RIF_SEM_DIS, RIF_CFEN) /* PG0 */
		RIFPROT(RIF_IOPORT_PIN(1), RIF_UNUSED,  RIF_UNLOCK, RIF_SEC, RIF_PRIV, RIF_CID1, RIF_SEM_DIS, RIF_CFEN) /* PG1 */
		RIFPROT(RIF_IOPORT_PIN(2), RIF_UNUSED,  RIF_UNLOCK, RIF_SEC, RIF_PRIV, RIF_CID1, RIF_SEM_DIS, RIF_CFEN) /* PG2 */
		RIFPROT(RIF_IOPORT_PIN(3), RIF_UNUSED,  RIF_UNLOCK, RIF_SEC, RIF_PRIV, RIF_CID1, RIF_SEM_DIS, RIF_CFEN) /* PG3 */
		RIFPROT(RIF_IOPORT_PIN(4), RIF_UNUSED,  RIF_UNLOCK, RIF_NSEC, RIF_PRIV, RIF_CID1, RIF_SEM_DIS, RIF_CFEN) /* PG4 */
		RIFPROT(RIF_IOPORT_PIN(5), RIF_UNUSED,  RIF_UNLOCK, RIF_NSEC, RIF_PRIV, RIF_CID1, RIF_SEM_DIS, RIF_CFEN) /* PG5 */
		RIFPROT(RIF_IOPORT_PIN(6), RIF_UNUSED,  RIF_UNLOCK, RIF_NSEC, RIF_PRIV, RIF_CID1, RIF_SEM_DIS, RIF_CFEN) /* PG6 */
		RIFPROT(RIF_IOPORT_PIN(7), RIF_UNUSED,  RIF_UNLOCK, RIF_NSEC, RIF_PRIV, RIF_CID1, RIF_SEM_DIS, RIF_CFEN) /* PG7 */
		RIFPROT(RIF_IOPORT_PIN(8), RIF_UNUSED,  RIF_UNLOCK, RIF_NSEC, RIF_PRIV, RIF_CID1, RIF_SEM_DIS, RIF_CFEN) /* PG8 */
		RIFPROT(RIF_IOPORT_PIN(9), RIF_UNUSED,  RIF_UNLOCK, RIF_SEC, RIF_PRIV, RIF_CID2, RIF_SEM_DIS, RIF_CFEN) /* PG9 */
		RIFPROT(RIF_IOPORT_PIN(10), RIF_UNUSED,  RIF_UNLOCK, RIF_SEC, RIF_PRIV, RIF_CID2, RIF_SEM_DIS, RIF_CFEN) /* PG10 */
		RIFPROT(RIF_IOPORT_PIN(11), RIF_UNUSED,  RIF_UNLOCK, RIF_NSEC, RIF_PRIV, RIF_CID1, RIF_SEM_DIS, RIF_CFEN) /* PG11 */
		RIFPROT(RIF_IOPORT_PIN(12), RIF_UNUSED,  RIF_UNLOCK, RIF_NSEC, RIF_PRIV, RIF_CID1, RIF_SEM_DIS, RIF_CFEN) /* PG12 */
		RIFPROT(RIF_IOPORT_PIN(13), RIF_UNUSED,  RIF_UNLOCK, RIF_NSEC, RIF_PRIV, RIF_CID2, RIF_SEM_DIS, RIF_CFEN) /* PG13 */
		RIFPROT(RIF_IOPORT_PIN(14), RIF_UNUSED,  RIF_UNLOCK, RIF_NSEC, RIF_PRIV, RIF_CID1, RIF_SEM_DIS, RIF_CFEN) /* PG14 */
		RIFPROT(RIF_IOPORT_PIN(15), RIF_UNUSED,  RIF_UNLOCK, RIF_NSEC, RIF_PRIV, RIF_CID1, RIF_SEM_DIS, RIF_CFEN) /* PG15 */
	>;
};

&gpioh{

	st,protreg = <
		RIFPROT(RIF_IOPORT_PIN(2), RIF_UNUSED,  RIF_UNLOCK, RIF_NSEC, RIF_PRIV, RIF_CID1, RIF_SEM_DIS, RIF_CFEN) /* PH2 */
		RIFPROT(RIF_IOPORT_PIN(3), RIF_UNUSED,  RIF_UNLOCK, RIF_NSEC, RIF_PRIV, RIF_CID1, RIF_SEM_DIS, RIF_CFEN) /* PH3 */
		RIFPROT(RIF_IOPORT_PIN(4), RIF_UNUSED,  RIF_UNLOCK, RIF_NSEC, RIF_PRIV, RIF_CID1, RIF_SEM_DIS, RIF_CFEN) /* PH4 */
		RIFPROT(RIF_IOPORT_PIN(5), RIF_UNUSED,  RIF_UNLOCK, RIF_SEC, RIF_PRIV, RIF_CID1, RIF_SEM_DIS, RIF_CFEN) /* PH5 */
		RIFPROT(RIF_IOPORT_PIN(6), RIF_UNUSED,  RIF_UNLOCK, RIF_NSEC, RIF_PRIV, RIF_CID1, RIF_SEM_DIS, RIF_CFEN) /* PH6 */
		RIFPROT(RIF_IOPORT_PIN(7), RIF_UNUSED,  RIF_UNLOCK, RIF_NSEC, RIF_PRIV, RIF_CID1, RIF_SEM_DIS, RIF_CFEN) /* PH7 */
		RIFPROT(RIF_IOPORT_PIN(8), RIF_UNUSED,  RIF_UNLOCK, RIF_NSEC, RIF_PRIV, RIF_CID1, RIF_SEM_DIS, RIF_CFEN) /* PH8 */
		RIFPROT(RIF_IOPORT_PIN(9), RIF_UNUSED,  RIF_UNLOCK, RIF_NSEC, RIF_PRIV, RIF_CID1, RIF_SEM_DIS, RIF_CFEN) /* PH9 */
		RIFPROT(RIF_IOPORT_PIN(10), RIF_UNUSED,  RIF_UNLOCK, RIF_NSEC, RIF_PRIV, RIF_CID1, RIF_SEM_DIS, RIF_CFEN) /* PH10 */
		RIFPROT(RIF_IOPORT_PIN(11), RIF_UNUSED,  RIF_UNLOCK, RIF_NSEC, RIF_PRIV, RIF_CID1, RIF_SEM_DIS, RIF_CFEN) /* PH11 */
		RIFPROT(RIF_IOPORT_PIN(12), RIF_UNUSED,  RIF_UNLOCK, RIF_NSEC, RIF_PRIV, RIF_CID1, RIF_SEM_DIS, RIF_CFEN) /* PH12 */
		RIFPROT(RIF_IOPORT_PIN(13), RIF_UNUSED,  RIF_UNLOCK, RIF_NSEC, RIF_PRIV, RIF_CID1, RIF_SEM_DIS, RIF_CFEN) /* PH13 */
	>;
};

&gpioi{

	st,protreg = <
		RIFPROT(RIF_IOPORT_PIN(0), RIF_UNUSED,  RIF_UNLOCK, RIF_NSEC, RIF_PRIV, RIF_CID1, RIF_SEM_DIS, RIF_CFEN) /* PI0 */
		RIFPROT(RIF_IOPORT_PIN(1), RIF_UNUSED,  RIF_UNLOCK, RIF_NSEC, RIF_NPRIV, RIF_CID2, RIF_SEM_DIS, RIF_CFEN) /* PI1 */
		RIFPROT(RIF_IOPORT_PIN(2), EMPTY_SEMWL,  RIF_UNLOCK, RIF_NSEC, RIF_PRIV, RIF_UNUSED, RIF_SEM_EN, RIF_CFEN) /* PI2 */
		RIFPROT(RIF_IOPORT_PIN(3), RIF_UNUSED,  RIF_UNLOCK, RIF_NSEC, RIF_PRIV, RIF_CID1, RIF_SEM_DIS, RIF_CFEN) /* PI3 */
		RIFPROT(RIF_IOPORT_PIN(4), RIF_UNUSED,  RIF_UNLOCK, RIF_NSEC, RIF_PRIV, RIF_CID1, RIF_SEM_DIS, RIF_CFEN) /* PI4 */
		RIFPROT(RIF_IOPORT_PIN(5), RIF_UNUSED,  RIF_UNLOCK, RIF_NSEC, RIF_PRIV, RIF_CID1, RIF_SEM_DIS, RIF_CFEN) /* PI5 */
		RIFPROT(RIF_IOPORT_PIN(6), RIF_UNUSED,  RIF_UNLOCK, RIF_SEC, RIF_NPRIV, RIF_CID1, RIF_SEM_DIS, RIF_CFEN) /* PI6 */
		RIFPROT(RIF_IOPORT_PIN(7), RIF_UNUSED,  RIF_UNLOCK, RIF_NSEC, RIF_PRIV, RIF_CID1, RIF_SEM_DIS, RIF_CFEN) /* PI7 */
		RIFPROT(RIF_IOPORT_PIN(8), RIF_UNUSED,  RIF_UNLOCK, RIF_SEC, RIF_PRIV, RIF_CID1, RIF_SEM_DIS, RIF_CFEN) /* PI8 */
		RIFPROT(RIF_IOPORT_PIN(9), RIF_UNUSED,  RIF_UNLOCK, RIF_NSEC, RIF_PRIV, RIF_CID1, RIF_SEM_DIS, RIF_CFEN) /* PI9 */
		RIFPROT(RIF_IOPORT_PIN(10), RIF_UNUSED,  RIF_UNLOCK, RIF_NSEC, RIF_PRIV, RIF_CID1, RIF_SEM_DIS, RIF_CFEN) /* PI10 */
		RIFPROT(RIF_IOPORT_PIN(11), RIF_UNUSED,  RIF_UNLOCK, RIF_NSEC, RIF_PRIV, RIF_CID1, RIF_SEM_DIS, RIF_CFEN) /* PI11 */
		RIFPROT(RIF_IOPORT_PIN(12), RIF_UNUSED,  RIF_UNLOCK, RIF_NSEC, RIF_PRIV, RIF_CID1, RIF_SEM_DIS, RIF_CFEN) /* PI12 */
		RIFPROT(RIF_IOPORT_PIN(13), RIF_UNUSED,  RIF_UNLOCK, RIF_NSEC, RIF_PRIV, RIF_CID1, RIF_SEM_DIS, RIF_CFEN) /* PI13 */
		RIFPROT(RIF_IOPORT_PIN(14), EMPTY_SEMWL,  RIF_UNLOCK, RIF_NSEC, RIF_PRIV, RIF_UNUSED, RIF_SEM_EN, RIF_CFEN) /* PI14 */
		RIFPROT(RIF_IOPORT_PIN(15), EMPTY_SEMWL,  RIF_UNLOCK, RIF_NSEC, RIF_NPRIV, RIF_UNUSED, RIF_SEM_EN, RIF_CFEN) /* PI15 */
	>;
};

&gpioj{

	st,protreg = <
		RIFPROT(RIF_IOPORT_PIN(0), RIF_UNUSED,  RIF_UNLOCK, RIF_NSEC, RIF_PRIV, RIF_CID1, RIF_SEM_DIS, RIF_CFEN) /* PJ0 */
		RIFPROT(RIF_IOPORT_PIN(1), RIF_UNUSED,  RIF_UNLOCK, RIF_NSEC, RIF_PRIV, RIF_CID1, RIF_SEM_DIS, RIF_CFEN) /* PJ1 */
		RIFPROT(RIF_IOPORT_PIN(2), RIF_UNUSED,  RIF_UNLOCK, RIF_NSEC, RIF_PRIV, RIF_CID1, RIF_SEM_DIS, RIF_CFEN) /* PJ2 */
		RIFPROT(RIF_IOPORT_PIN(3), RIF_UNUSED,  RIF_UNLOCK, RIF_NSEC, RIF_PRIV, RIF_CID1, RIF_SEM_DIS, RIF_CFEN) /* PJ3 */
		RIFPROT(RIF_IOPORT_PIN(4), RIF_UNUSED,  RIF_UNLOCK, RIF_NSEC, RIF_PRIV, RIF_CID1, RIF_SEM_DIS, RIF_CFEN) /* PJ4 */
		RIFPROT(RIF_IOPORT_PIN(5), RIF_UNUSED,  RIF_UNLOCK, RIF_NSEC, RIF_PRIV, RIF_CID1, RIF_SEM_DIS, RIF_CFEN) /* PJ5 */
		RIFPROT(RIF_IOPORT_PIN(6), RIF_UNUSED,  RIF_UNLOCK, RIF_NSEC, RIF_NPRIV, RIF_CID2, RIF_SEM_DIS, RIF_CFEN) /* PJ6 */
		RIFPROT(RIF_IOPORT_PIN(7), RIF_UNUSED,  RIF_UNLOCK, RIF_NSEC, RIF_PRIV, RIF_CID1, RIF_SEM_DIS, RIF_CFEN) /* PJ7 */
		RIFPROT(RIF_IOPORT_PIN(8), RIF_UNUSED,  RIF_UNLOCK, RIF_NSEC, RIF_PRIV, RIF_CID2, RIF_SEM_DIS, RIF_CFEN) /* PJ8 */
		RIFPROT(RIF_IOPORT_PIN(9), RIF_UNUSED,  RIF_UNLOCK, RIF_NSEC, RIF_PRIV, RIF_CID1, RIF_SEM_DIS, RIF_CFEN) /* PJ9 */
		RIFPROT(RIF_IOPORT_PIN(10), EMPTY_SEMWL,  RIF_UNLOCK, RIF_NSEC, RIF_PRIV, RIF_UNUSED, RIF_SEM_EN, RIF_CFEN) /* PJ10 */
		RIFPROT(RIF_IOPORT_PIN(11), RIF_UNUSED,  RIF_UNLOCK, RIF_NSEC, RIF_PRIV, RIF_CID1, RIF_SEM_DIS, RIF_CFEN) /* PJ11 */
		RIFPROT(RIF_IOPORT_PIN(12), RIF_UNUSED,  RIF_UNLOCK, RIF_NSEC, RIF_PRIV, RIF_CID1, RIF_SEM_DIS, RIF_CFEN) /* PJ12 */
		RIFPROT(RIF_IOPORT_PIN(13), RIF_UNUSED,  RIF_UNLOCK, RIF_NSEC, RIF_PRIV, RIF_CID1, RIF_SEM_DIS, RIF_CFEN) /* PJ13 */
		RIFPROT(RIF_IOPORT_PIN(14), RIF_UNUSED,  RIF_UNLOCK, RIF_NSEC, RIF_PRIV, RIF_CID1, RIF_SEM_DIS, RIF_CFEN) /* PJ14 */
		RIFPROT(RIF_IOPORT_PIN(15), RIF_UNUSED,  RIF_UNLOCK, RIF_NSEC, RIF_PRIV, RIF_CID1, RIF_SEM_DIS, RIF_CFEN) /* PJ15 */
	>;
};

&gpiok{

	st,protreg = <
		RIFPROT(RIF_IOPORT_PIN(0), RIF_UNUSED,  RIF_UNLOCK, RIF_NSEC, RIF_PRIV, RIF_CID1, RIF_SEM_DIS, RIF_CFEN) /* PK0 */
		RIFPROT(RIF_IOPORT_PIN(1), EMPTY_SEMWL,  RIF_UNLOCK, RIF_NSEC, RIF_PRIV, RIF_UNUSED, RIF_SEM_EN, RIF_CFEN) /* PK1 */
		RIFPROT(RIF_IOPORT_PIN(2), EMPTY_SEMWL,  RIF_UNLOCK, RIF_NSEC, RIF_NPRIV, RIF_UNUSED, RIF_SEM_EN, RIF_CFEN) /* PK2 */
		RIFPROT(RIF_IOPORT_PIN(3), RIF_UNUSED,  RIF_UNLOCK, RIF_NSEC, RIF_PRIV, RIF_CID1, RIF_SEM_DIS, RIF_CFEN) /* PK3 */
		RIFPROT(RIF_IOPORT_PIN(4), RIF_UNUSED,  RIF_UNLOCK, RIF_NSEC, RIF_NPRIV, RIF_CID1, RIF_SEM_DIS, RIF_CFEN) /* PK4 */
		RIFPROT(RIF_IOPORT_PIN(5), EMPTY_SEMWL,  RIF_UNLOCK, RIF_NSEC, RIF_NPRIV, RIF_UNUSED, RIF_SEM_EN, RIF_CFEN) /* PK5 */
		RIFPROT(RIF_IOPORT_PIN(6), EMPTY_SEMWL,  RIF_UNLOCK, RIF_NSEC, RIF_NPRIV, RIF_UNUSED, RIF_SEM_EN, RIF_CFEN) /* PK6 */
		RIFPROT(RIF_IOPORT_PIN(7), RIF_UNUSED,  RIF_UNLOCK, RIF_NSEC, RIF_PRIV, RIF_CID1, RIF_SEM_DIS, RIF_CFEN) /* PK7 */
	>;
};

&gpioz{

	st,protreg = <
		RIFPROT(RIF_IOPORT_PIN(0), RIF_UNUSED,  RIF_UNLOCK, RIF_NSEC, RIF_PRIV, RIF_CID1, RIF_SEM_DIS, RIF_CFEN) /* PZ0 */
		RIFPROT(RIF_IOPORT_PIN(1), RIF_UNUSED,  RIF_UNLOCK, RIF_NSEC, RIF_PRIV, RIF_CID1, RIF_SEM_DIS, RIF_CFEN) /* PZ1 */
		RIFPROT(RIF_IOPORT_PIN(2), RIF_UNUSED,  RIF_UNLOCK, RIF_NSEC, RIF_PRIV, RIF_CID1, RIF_SEM_DIS, RIF_CFEN) /* PZ2 */
		RIFPROT(RIF_IOPORT_PIN(3), EMPTY_SEMWL,  RIF_UNLOCK, RIF_NSEC, RIF_PRIV, RIF_UNUSED, RIF_SEM_EN, RIF_CFEN) /* PZ3 */
		RIFPROT(RIF_IOPORT_PIN(4), EMPTY_SEMWL,  RIF_UNLOCK, RIF_NSEC, RIF_PRIV, RIF_UNUSED, RIF_SEM_EN, RIF_CFEN) /* PZ4 */
		RIFPROT(RIF_IOPORT_PIN(5), RIF_UNUSED,  RIF_UNLOCK, RIF_NSEC, RIF_PRIV, RIF_CID1, RIF_SEM_DIS, RIF_CFEN) /* PZ5 */
		RIFPROT(RIF_IOPORT_PIN(6), RIF_UNUSED,  RIF_UNLOCK, RIF_NSEC, RIF_PRIV, RIF_CID1, RIF_SEM_DIS, RIF_CFEN) /* PZ6 */
		RIFPROT(RIF_IOPORT_PIN(7), EMPTY_SEMWL,  RIF_UNLOCK, RIF_NSEC, RIF_PRIV, RIF_UNUSED, RIF_SEM_EN, RIF_CFEN) /* PZ7 */
		RIFPROT(RIF_IOPORT_PIN(8), EMPTY_SEMWL,  RIF_UNLOCK, RIF_NSEC, RIF_PRIV, RIF_UNUSED, RIF_SEM_EN, RIF_CFEN) /* PZ8 */
		RIFPROT(RIF_IOPORT_PIN(9), RIF_UNUSED,  RIF_UNLOCK, RIF_NSEC, RIF_PRIV, RIF_CID1, RIF_SEM_DIS, RIF_CFEN) /* PZ9 */
	>;
};

&ipcc2{
	st,protreg = <
		RIFPROT(RIF_IPCC_CPU1_CHANNEL(1), RIF_UNUSED, RIF_UNLOCK, RIF_NSEC, RIF_NPRIV, RIF_CID1, RIF_SEM_DIS, RIF_CFEN)
		RIFPROT(RIF_IPCC_CPU2_CHANNEL(1), RIF_UNUSED, RIF_UNLOCK, RIF_NSEC, RIF_NPRIV, RIF_CID3, RIF_SEM_DIS, RIF_CFEN)
		RIFPROT(RIF_IPCC_CPU1_CHANNEL(2), RIF_UNUSED, RIF_UNLOCK, RIF_NSEC, RIF_NPRIV, RIF_CID1, RIF_SEM_DIS, RIF_CFEN)
		RIFPROT(RIF_IPCC_CPU2_CHANNEL(2), RIF_UNUSED, RIF_UNLOCK, RIF_NSEC, RIF_NPRIV, RIF_CID3, RIF_SEM_DIS, RIF_CFEN)
		RIFPROT(RIF_IPCC_CPU1_CHANNEL(3), RIF_UNUSED, RIF_UNLOCK, RIF_NSEC, RIF_NPRIV, RIF_CID1, RIF_SEM_DIS, RIF_CFEN)
		RIFPROT(RIF_IPCC_CPU2_CHANNEL(3), RIF_UNUSED, RIF_UNLOCK, RIF_NSEC, RIF_NPRIV, RIF_CID3, RIF_SEM_DIS, RIF_CFEN)
		RIFPROT(RIF_IPCC_CPU1_CHANNEL(4), RIF_UNUSED, RIF_UNLOCK, RIF_NSEC, RIF_NPRIV, RIF_CID1, RIF_SEM_DIS, RIF_CFEN)
		RIFPROT(RIF_IPCC_CPU2_CHANNEL(4), RIF_UNUSED, RIF_UNLOCK, RIF_NSEC, RIF_NPRIV, RIF_CID3, RIF_SEM_DIS, RIF_CFEN)
	>;
};

